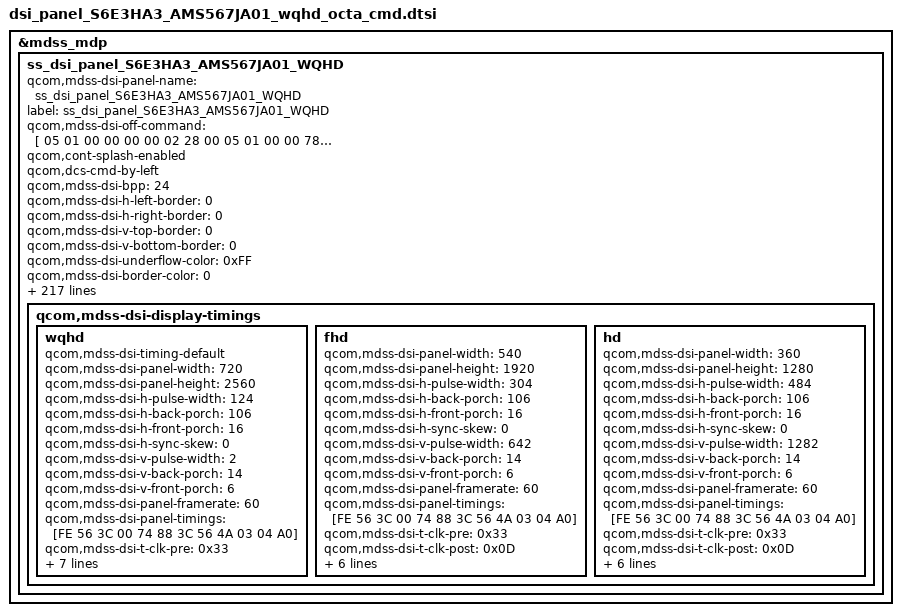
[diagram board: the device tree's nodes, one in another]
/* Copyright (c) 2012, Samsung Electronics Corporation. All rights reserved.
 *
 * This program is free software; you can redistribute it and/or modify
 * it under the terms of the GNU General Public License version 2 and
 * only version 2 as published by the Free Software Foundation.
 *
 * This program is distributed in the hope that it will be useful,
 * but WITHOUT ANY WARRANTY; without even the implied warranty of
 * MERCHANTABILITY or FITNESS FOR A PARTICULAR PURPOSE.  See the
 * GNU General Public License for more details.
 */

&mdss_mdp {
	ss_dsi_panel_S6E3HA3_AMS567JA01_WQHD: ss_dsi_panel_S6E3HA3_AMS567JA01_WQHD {
		qcom,mdss-dsi-panel-name = "ss_dsi_panel_S6E3HA3_AMS567JA01_WQHD";
		label = "ss_dsi_panel_S6E3HA3_AMS567JA01_WQHD";

		qcom,mdss-dsi-off-command=[
			05 01 00 00 00 00 02 28 00
			05 01 00 00 78 00 02 10 00	/* wait 120ms(0x78) */
		];

		qcom,cont-splash-enabled;
		qcom,dcs-cmd-by-left;
		/*qcom,cmd-sync-wait-broadcast;*/
		/*qcom,cmd-sync-wait-trigger;*/
		/*qcom,mdss-dsi-fbc-enable=*/
		/*qcom,mdss-dsi-fbc-bpp=*/
		/*qcom,mdss-dsi-fbc-packing=*/
		/*qcom,mdss-dsi-fbc-quant-error=*/
		/*qcom,mdss-dsi-fbc-bias=*/
		/*qcom,mdss-dsi-fbc-pat-mode=*/
		/*qcom,mdss-dsi-fbc-vlc-mode=*/
		/*qcom,mdss-dsi-fbc-bflc-mode=*/
		/*qcom,mdss-dsi-fbc-h-line-budget=*/
		/*qcom,mdss-dsi-fbc-budget-ctrl=*/
		/*qcom,mdss-dsi-fbc-block-budget=*/
		/*qcom,mdss-dsi-fbc-lossless-threshold=*/
		/*qcom,mdss-dsi-fbc-lossy-threshold=*/
		/*qcom,mdss-dsi-fbc-rgb-threshold=*/
		/*qcom,mdss-dsi-fbc-lossy-mode-idx=*/

		qcom,mdss-dsi-bpp = <24>;
		qcom,mdss-dsi-h-left-border = <0>;
		qcom,mdss-dsi-h-right-border = <0>;
		qcom,mdss-dsi-v-top-border = <0>;
		qcom,mdss-dsi-v-bottom-border = <0>;

		qcom,mdss-dsi-underflow-color = <0xFF>;
		qcom,mdss-dsi-border-color = <0>;

		/*qcom,mdss-dsi-pan-enable-dynamic-fps=*/
		/*qcom,mdss-dsi-pan-fps-update=*/

		qcom,mdss-dsi-bl-pmic-control-type = "bl_ctrl_dcs";
		/*qcom,mdss-dsi-bl-pmic-bank-select=*/
		/*qcom,mdss-dsi-bl-pmic-pwm-frequency=*/
		/*qcom,mdss-dsi-pwm-gpio=*/

		qcom,mdss-dsi-bl-min-level = <1>;
		qcom,mdss-dsi-bl-max-level = <365>;
		qcom,mdss-brightness-max-level = <365>;
		qcom,mdss-dsi-interleave-mode = <0>;
		qcom,mdss-dsi-panel-type = "dsi_cmd_mode";

		/*qcom,mdss-dsi-te-check-enable; */
		qcom,mdss-dsi-te-using-te-pin;
		qcom,mdss-dsi-te-pin-select = <1>;

		qcom,mdss-dsi-te-dcs-command = <1>;
		qcom,mdss-dsi-wr-mem-start = <0x2C>;
		qcom,mdss-dsi-wr-mem-continue = <0x3C>;

		/* CMD mode panel doesn't need below stuff */
		/*qcom,mdss-dsi-h-sync-pulse=*/
		/*qcom,mdss-dsi-hfp-power-mode=*/
		/*qcom,mdss-dsi-hbp-power-mode=*/
		/*qcom,mdss-dsi-hsa-power-mode=*/
		/*qcom,mdss-dsi-last-line-interleave=*/
		/*qcom,mdss-dsi-bllp-eof-power-mode=*/
		/*qcom,mdss-dsi-bllp-power-mode=*/
		/*qcom,mdss-dsi-traffic-mode=*/

		qcom,mdss-dsi-pixel-packing = "loose";

		qcom,mdss-dsi-virtual-channel-id = <0>;
		qcom,mdss-dsi-color-order = "rgb_swap_rgb";
		qcom,mdss-dsi-lane-0-state;
		qcom,mdss-dsi-lane-1-state;
		qcom,mdss-dsi-lane-2-state;
		qcom,mdss-dsi-lane-3-state;
		qcom,mdss-dsi-lane-map = "lane_map_0123";

		qcom,mdss-dsi-t-clk-pre = <0x33>;
		qcom,mdss-dsi-t-clk-post = <0x0D>;

		qcom,mdss-dsi-stream = <0>;
		qcom,mdss-dsi-mdp-trigger = "none";
		qcom,mdss-dsi-dma-trigger = "trigger_sw";
		qcom,mdss-dsi-panel-framerate = <60>;
/*		qcom,mdss-dsi-panel-clockrate = <980500000>;*/

		qcom,mdss-dsi-off-command-state = "dsi_hs_mode";

		qcom,mdss-pan-physical-width-dimension = <63>; /* 63.36*/
		qcom,mdss-pan-physical-height-dimension = <113>; /* 112.64 */

		qcom,mdss-dsi-panel-mode-gpio-state = "invalid";

		/*qcom,mdss-tear-check-disable*/
		/*qcom,mdss-tear-check-sync-cfg-height = <2576>;*/
		/*qcom,mdss-tear-check-sync-init-val=*/
		/*qcom,mdss-tear-check-sync-threshold-start=*/
		/*qcom,mdss-tear-check-sync-threshold-continue=*/
		/*qcom,mdss-tear-check-start-pos=*/
		/*qcom,mdss-tear-check-rd-ptr-trigger-intr=*/
		/*qcom,mdss-tear-check-frame-rate=*/

		qcom,mdss-dsi-reset-sequence = <1 5>, <0 5>, <1 5>;
		qcom,partial-update-enabled;
		qcom,partial-update-roi-merge;

		/*qcom,mdss-dsi-horizontal-line-idle*/

		qcom,mdss-dsi-lp11-init;
		qcom,mdss-dsi-init-delay-us = <1000>;

		qcom,mdss-dsi-rx-eot-ignore;
		qcom,mdss-dsi-tx-eot-append;

		qcom,ulps-enabled;
		/* qcom,suspend-ulps-enabled; */
		qcom,esd-check-enabled;
		qcom,mdss-dsi-panel-status-check-mode ="reg_read_irq";
		qcom,mdss-dsi-panel-status-value=<1>;
		qcom,mdss-dsi-panel-status-irq-trigger1 = "rising";
		qcom,mdss-dsi-panel-status-irq-trigger2 = "falling";

		samsung,esd_recovery_1_tx_cmds_revA = [
			07 00 00 00 00 00 01 00
			05 00 00 00 00 00 01 38
			05 00 00 00 00 00 01 2c
			29 00 00 00 00 00 03 F0 5A 5A
			29 00 00 00 00 00 05 F6 43 17 37 50
			29 01 00 00 00 00 03 F0 A5 A5
		];

		samsung,esd_recovery_2_tx_cmds_revA = [
			07 00 00 00 00 00 01 00
			05 00 00 00 00 00 01 38
			05 00 00 00 00 00 01 2c
			29 00 00 00 00 00 03 F0 5A 5A
			29 00 00 00 00 00 05 F6 43 17 37 10
			29 01 00 00 00 00 03 F0 A5 A5
		];

/*
* ************************************************************************************************************************************
*
*
*			Below  parameters are samsung dependent thigs
*
*
* ************************************************************************************************************************************
*/
		samsung,support_panel_max = <1>;
		samsung,hw-config = "split_dsi";
		samsung,panel-lpm-enable;
		samsung,support_irc;
		samsung,elvss_interpolation_temperature = <(-15)>;
		samsung,support_factory_panel_swap;
		samsung,support_multires;

		/*
		* ************************************************************************************************************************
		*  Tx
		* ************************************************************************************************************************
		*/

		samsung,level1_key_enable_tx_cmds_revA = [
			29 01 00 00 00 00 03 F0 5A 5A
		];
		samsung,level1_key_disable_tx_cmds_revA = [
			29 01 00 00 00 00 03 F0 A5 A5
		];
		samsung,level2_key_enable_tx_cmds_revA = [
			29 01 00 00 00 00 03 F2 5A 5A
		];
		samsung,level2_key_disable_tx_cmds_revA = [
			29 01 00 00 00 00 03 F2 A5 A5
		];

		samsung,packet_size_tx_cmds_revA = [
			37 01 00 00 00 00 02 07 00
		];

		samsung,reg_read_pos_tx_cmds_revA = [
			15 01 00 00 00 00 02 B0 00
		];

		samsung,manufacture_read_pre_tx_cmds_revA = [
			05 01 00 00 05 00 01 11
			29 01 00 00 00 00 03 F0 5A 5A
		];

		samsung,display_on_tx_cmds_revA = [
			29 00 00 00 00 00 03 F0 5A 5A 		/* TEST KEY1 Enable */
			29 00 00 00 00 00 02 C4 03			/* Dual DSI */
			29 00 00 00 00 00 02 F9 03			/* MIC disable */
			29 00 00 00 00 00 03 F0 A5 A5		/* TEST KEY key Disable  */
			05 01 00 00 00 00 02 29 00
		];
		samsung,display_off_tx_cmds_revA = [05 01 00 00 00 00 02 28 00];

		/*
		* ************************************************************************************************************************
		*  Rx
		* ************************************************************************************************************************
		*/

		/*
			the last byte in read commands	represent READ LENGH, like below  READ LENGH = 0x21
		*/

		samsung,manufacture_id0_rx_cmds_revA = [ 06 01 00 00 00 00 01 da 01 00];
		samsung,manufacture_id1_rx_cmds_revA = [ 06 01 00 00 00 00 01 db 01 00];
		samsung,manufacture_id2_rx_cmds_revA = [ 06 01 00 00 00 00 01 dc 01 00];

		samsung,manufacture_id_rx_cmds_revA = [ 06 01 00 00 00 00 01 04 03 00];

		samsung,manufacture_date_rx_cmds_revA = [ 06 01 00 00 00 00 01 c8 04 28];	/* read C8 41~44th , 40=0x28*/

		samsung,cell_id_rx_cmds_revA = [ 06 01 00 00 00 00 01 C8 07 28]; /* read C8 41~47th */

		samsung,ddi_id_rx_cmds_revA = [ 06 01 00 00 00 00 01 D6 05 00]; /* read D6 1th~5th */

		samsung,ldi_debug0_rx_cmds_revA = [06 01 00 00 00 00 01 0A 01 00];
		samsung,ldi_debug1_rx_cmds_revA = [06 01 00 00 00 00 01 ED 01 00];
		samsung,ldi_debug2_rx_cmds_revA = [06 01 00 00 00 00 01 EE 01 00];

		samsung,mtp_read_sysfs_rx_cmds_revA = [ 06 01 00 00 00 00 01 00 00 00];

		samsung,smart_dimming_mtp_rx_cmds_revA = [ 06 01 00 00 00 00 01 c8 23 00];

		samsung,mdnie_read_rx_cmds_revA = [ 06 01 00 00 00 00 01 A1 04 00];

		/*
		* ************************************************************************************************************************
		*  FPS change
		* ************************************************************************************************************************
		*/

		samsung,ldi_fps_change_tx_cmds_revA = [
			29 00 00 00 00 00 03 F0 5A 5A
			29 00 00 00 00 00 03 FC 5A 5A
			29 00 00 00 00 00 04 F2 63 41 C5	/* C5 => hsync timing: 453*/
			29 00 00 00 00 00 03 F0 A5 A5
			29 01 00 00 00 00 03 FC A5 A5
		];

		samsung,spi_enable_tx_cmds_revA = [
			29 01 00 00 00 00 03 F0 5A 5A
			29 01 00 00 00 00 03 FC 5A 5A
			29 01 00 00 00 00 02 B0 13
			29 01 00 00 00 00 02 D8 02
			29 01 00 00 00 00 02 B0 1F
			29 01 00 00 1E 00 02 FE 06
			29 01 00 00 00 00 03 F0 A5 A5
			29 01 00 00 00 00 03 FC A5 A5
		];

		samsung,ldi_fps_rx_cmds_revA = [06 01 00 00 00 00 01 D7 01 1A]; /* read D7 27th , 27=0x1B*/

		/*
		 * ************************************************************************************************************************
		 *   APLPM
		 * ************************************************************************************************************************
		 */

		/*
		 * The command set of R53h will be replaced with
		 * lpm 2nit or 40nit tx commnad for
		 * changing brightness level
		 */
		samsung,alpm_on_tx_cmds_revA = [
			29 01 00 00 00 00 03 F0 5A 5A		/* TEST KEY Enable */

			/* mDNIe BYPASS */
			39 01 00 00 00 00 3A
				DF 00 00 00 67 a9 0c 0c 0c 0c
				00 aa ab 00 aa ab 00 aa ab 00
				aa ab ff 00 00 ff ff 00 ff 00
				ff ff ff ff 00 ff ff 00 ff 00
				ff 00 00 ff ff 00 ff 00 ff 00
				00 ff ff 00 ff 00 ff 00
			39 01 00 00 00 00 87
				DE 00 24 96 b3 01 0e 01 00 77
				03 07 40 00 08 04 04 01 80 28
				3e 7e a0 28 18 a0 07 65 06 03
				00 40 00 00 10 00 00 30 00 00
				00 30 00 00 30 00 00 00 ff 01
				00 00 07 ff 07 ff 14 00 0a 00
				32 01 f4 0b 8a 6e 99 1b 17 1e
				1b 02 5f 03 33 02 c8 02 22 10
				10 07 07 20 2d 01 00 00 20 00
				20 00 20 00 20 00 20 00 20 00
				20 00 20 00 20 00 20 00 20 00
				20 00 20 00 20 00 20 00 20 00
				20 00 20 00 20 00 20 00 20 00
				20 00 20 00 ff
			39 01 00 00 00 00 10
				DD 01 00 00 00 00 00 00 00 00
				00 00 00 00 00 00

			29 01 00 00 00 00 02 BB C4			/* HLPM(0x54)/ALPM(0xC4) Mode On */
			29 01 00 00 00 00 02 53 03			/* ALPM/HLPM 2nit On */
			29 01 00 00 01 00 02 F7 03			/* Gamma, LTPS(AID) update */
			29 01 00 00 00 00 02 F7 00
			29 01 00 00 00 00 03 F0 A5 A5
		];

		samsung,alpm_on_tx_cmds_revD = [
			29 01 00 00 00 00 03 F0 5A 5A		/* TEST KEY Enable */

			/* mDNIe BYPASS */
			39 01 00 00 00 00 3A
				DF 00 00 00 67 a9 0c 0c 0c 0c
				00 aa ab 00 aa ab 00 aa ab 00
				aa ab ff 00 00 ff ff 00 ff 00
				ff ff ff ff 00 ff ff 00 ff 00
				ff 00 00 ff ff 00 ff 00 ff 00
				00 ff ff 00 ff 00 ff 00
			39 01 00 00 00 00 87
				DE 00 24 96 b3 01 0e 01 00 77
				03 07 40 00 08 04 04 01 80 28
				3e 7e a0 28 18 a0 07 65 06 03
				00 40 00 00 10 00 00 30 00 00
				00 30 00 00 30 00 00 00 ff 01
				00 00 07 ff 07 ff 14 00 0a 00
				32 01 f4 0b 8a 6e 99 1b 17 1e
				1b 02 5f 03 33 02 c8 02 22 10
				10 07 07 20 2d 01 00 00 20 00
				20 00 20 00 20 00 20 00 20 00
				20 00 20 00 20 00 20 00 20 00
				20 00 20 00 20 00 20 00 20 00
				20 00 20 00 20 00 20 00 20 00
				20 00 20 00 ff
			39 01 00 00 00 00 10
				DD 01 00 00 00 00 00 00 00 00
				00 00 00 00 00 00

			29 01 00 00 00 00 02 BB C4			/* HLPM(0x54)/ALPM(0xC4) Mode On */
			29 01 00 00 00 00 02 53 03			/* ALPM/HLPM 2nit On */
			29 01 00 00 00 00 02 B8 00			/* IRC Setting(IRC OFF) */
			29 01 00 00 01 00 02 F7 03			/* Gamma, LTPS(AID) update */
			29 01 00 00 00 00 02 F7 00
			29 01 00 00 00 00 03 F0 A5 A5
		];

		samsung,alpm_off_tx_cmds_revA = [
			29 01 00 00 00 00 03 F0 5A 5A	/* TEST KEY Enable */
			05 01 00 00 00 00 02 28 00		/* display off wait 20ms */

			/* image write for normal mode */

			29 01 00 00 00 00 02 53 00		/* alpm off */
			29 01 00 00 00 00 02 F7 03		/* Gamma, LTPS(AID) update */
			29 01 00 00 00 00 03 F0 A5 A5	/* TEST KEY Disable */
		];

		samsung,lpm_2nit_tx_cmds_revA = [29 01 00 00 14 00 02 53 03];
		samsung,lpm_40nit_tx_cmds_revA = [29 01 00 00 14 00 02 53 02];

		samsung,lpm_hz_none_tx_cmds_revA = [29 01 00 00 00 00 02 00 00];

		/* HLPM added on REV A or later version */
		samsung,lpm_ctrl_alpm_tx_cmds_revA = [29 01 00 00 00 00 02 BB C4];
		samsung,lpm_ctrl_hlpm_tx_cmds_revA = [29 01 00 00 00 00 02 BB 54];

		/*
		* ************************************************************************************************************************
		*  VINT
		* ************************************************************************************************************************
		*/

		samsung,vint_tx_cmds_revA = [
			29 01 00 00 00 00 03 F4 AB 1E /* 420 ~ 21cd 0 */
			29 01 00 00 00 00 03 F4 AB 1D /* 20cd 1 */
			29 01 00 00 00 00 03 F4 AB 1C /* 19cd 2 */
			29 01 00 00 00 00 03 F4 AB 1B /* 17cd 3 */
			29 01 00 00 00 00 03 F4 AB 1A /* 16cd 4 */
			29 01 00 00 00 00 03 F4 AB 19 /* 15cd 5 */
			29 01 00 00 00 00 03 F4 AB 18 /* 14cd 6 */
			29 01 00 00 00 00 03 F4 AB 17 /* 13cd 7 */
			29 01 00 00 00 00 03 F4 AB 16 /* 12cd 8 */
			29 01 00 00 00 00 03 F4 AB 15 /* 11cd 9 */
			29 01 00 00 00 00 03 F4 AB 14 /* 10cd 10 */
			29 01 00 00 00 00 03 F4 AB 13 /* 9cd 11 */
			29 01 00 00 00 00 03 F4 AB 12 /* 8cd 12 */
			29 01 00 00 00 00 03 F4 AB 11 /* 7cd 13 */
			29 01 00 00 00 00 03 F4 AB 10 /* 6 ~ 2cd 14 */
		];

		samsung,vint_tx_cmds_revC = [
			29 01 00 00 00 00 03 F4 BB 1E /* 420 ~ 21cd 0 */
			29 01 00 00 00 00 03 F4 BB 1D /* 20cd 1 */
			29 01 00 00 00 00 03 F4 BB 1C /* 19cd 2 */
			29 01 00 00 00 00 03 F4 BB 1B /* 17cd 3 */
			29 01 00 00 00 00 03 F4 BB 1A /* 16cd 4 */
			29 01 00 00 00 00 03 F4 BB 19 /* 15cd 5 */
			29 01 00 00 00 00 03 F4 BB 18 /* 14cd 6 */
			29 01 00 00 00 00 03 F4 BB 17 /* 13cd 7 */
			29 01 00 00 00 00 03 F4 BB 16 /* 12cd 8 */
			29 01 00 00 00 00 03 F4 BB 15 /* 11cd 9 */
			29 01 00 00 00 00 03 F4 BB 14 /* 10cd 10 */
			29 01 00 00 00 00 03 F4 BB 13 /* 9cd 11 */
			29 01 00 00 00 00 03 F4 BB 12 /* 8cd 12 */
			29 01 00 00 00 00 03 F4 BB 11 /* 7cd 13 */
			29 01 00 00 00 00 03 F4 BB 10 /* 6 ~ 2cd 14 */
		];

		samsung,vint_map_table_revA = <
			2	14		3	14		4	14		5	14		6	14
			7	13		8	12		9	11		10	10		11	9
			12	8		13	7		14	6		15	5		16	4
			17	3		19	2		20	1		21	0		22	0
			24	0		25	0		27	0		29	0		30	0
			32	0		34	0		37	0		39	0		41	0
			44	0		47	0		50	0		53	0		56	0
			60	0		64	0		68	0		72	0		77	0
			82	0		87	0		93	0		98	0		105	0
			111	0		119	0		126	0		134	0		143	0
			152	0		162	0		172	0		183	0		195	0
			207	0		220	0		234	0		249	0		265	0
			282	0		300	0		316	0		333	0		350	0
			357	0		365	0		372	0		380	0		387	0
			395	0		403	0		412	0		420	0
		>;

		/*
		* ************************************************************************************************************************
		*  GAMMA
		* ************************************************************************************************************************
		*/

		samsung,gamma_tx_cmds_revA = [
			29 01 00 00 00 00 24		/* Brightness Condition Set - Gamma 2.2 Setting*/
			CA 01 00 01 00 01 00 80
			80 80 80 80 80 80 80 80
			80 80 80 80 80 80 80 80
			80 80 80 80 80 80 80 00
			00 00 00 00
			29 01 00 00 00 00 02 F7 03		/* Gamma, LTPS(AID) update */

			29 01 00 00 00 00 3C		/* dummy for single transmission more 100ns delay */
			00 00 00 00 00 00 00 00 00 00
			00 00 00 00 00 00 00 00 00 00
			00 00 00 00 00 00 00 00 00 00
			00 00 00 00 00 00 00 00 00 00
			00 00 00 00 00 00 00 00 00 00
			00 00 00 00 00 00 00 00 00 00

			29 01 00 00 00 00 02 F7 00
		];

		/*
		* ************************************************************************************************************************
		*  HBM
		* ************************************************************************************************************************
		*/

		samsung,enter_hbm_lux = <10000>;
		samsung,hbm_rx_cmds_revA = [ 06 01 00 00 00 00 01 B3 21 00];	/* read C8 51~65th , 50=0x32 */
		samsung,hbm2_rx_cmds_revA = [ 06 01 00 00 00 00 01 c8 14 44];	/* read C8 69~88th , 68=0x44 */

		samsung,hbm_gamma_tx_cmds_revA = [
			29 01 00 00 00 00 24		/* Brightness Condition Set - Gamma 2.2 Setting*/
				CA 01 00 01 00 01 00 80
				80 80 80 80 80 80 80 80
				80 80 80 80 80 80 80 80
				80 80 80 80 80 80 80 00
				00 00 00 00
		];

		samsung,hbm_etc_tx_cmds_revA = [
			29 00 00 00 00 00 0B B1 54 20 1A 33 5E 8C B3 D9 00 0A	/* AID 0% */
			29 01 00 00 00 00 03 B5 BC 00		/* ELVSS 2th elvss_offset */
			29 01 00 00 00 00 02 B0 15		/* ELVSS Setting */
			29 01 00 00 00 00 02 B5 00		/* ELVSS 22th Setting */
			29 01 00 00 00 00 05 B4 50 7F 12 0A 	 /* 1th : 0x50 32frame avg, 2th : 0x7F start point 50%, 4th: 0x0A ACL 8% */
			29 01 00 00 00 00 02 55 02		/* ACL ON */
			29 01 00 00 00 00 03 F4 AB 1E		/* VINT set*/
			29 01 00 00 00 00 02 F7 03
			29 01 00 00 00 00 02 F7 00
		];

		samsung,hbm_etc_tx_cmds_revC = [
			29 00 00 00 00 00 0B B1 54 20 1A 33 5E 8C B3 D9 00 0A	/* AID 0% */
			29 01 00 00 00 00 03 B5 BC 00		/* ELVSS 2th elvss_offset */
			29 01 00 00 00 00 02 B0 15		/* ELVSS Setting */
			29 01 00 00 00 00 02 B5 00		/* ELVSS 22th Setting */
			29 01 00 00 00 00 05 B4 50 7F 12 0A 	 /* 1th : 0x50 32frame avg, 2th : 0x7F start point 50%, 4th: 0x0A ACL 8% */
			29 01 00 00 00 00 02 55 02		/* ACL ON */
			29 01 00 00 00 00 03 F4 BB 1E		/* VINT set*/
			29 01 00 00 00 00 02 F7 03
			29 01 00 00 00 00 02 F7 00
		];

		samsung,hbm_irc_tx_cmds_revA = [
			29 00 00 00 00 00 15 B8 00 00
				00 00 00 00 00 00 00 00 00
				00 00 00 00 00 00 00 00 00
		];

		samsung,panel-hbm-off-cmds_revA = [
			15 01 00 00 00 00 02 53 00		/* HBM off*/
		];

		samsung,ccb_on_tx_cmds_revA = [
			29 01 00 00 00 00 03 B7 00 3F
		];

		samsung,ccb_off_tx_cmds_revA = [
			29 01 00 00 00 00 03 B7 00 2A
		];

		/*
		* ************************************************************************************************************************
		*  IRC
		* ************************************************************************************************************************
		*/

		samsung,irc_tx_cmds_revA = [
			29 00 00 00 00 00 15 B8 00 00
				00 00 00 00 00 00 00 00 00
				00 00 00 00 00 00 00 00 00
		];

		samsung,irc_off_tx_cmds_revA = [
			29 01 00 00 00 00 02 B8 00	 /* IRC OFF */
		];

		/*
		* ************************************************************************************************************************
		* AID command list and mappings
		* ************************************************************************************************************************
		*/
		samsung,aid_tx_cmds_revA = [
			29 01 00 00 00 00 0B B1 54 20 1A 33 5E 8C B3 D9 90 DE
			29 01 00 00 00 00 0B B1 54 20 1A 33 5E 8C B3 D9 90 C1
			29 01 00 00 00 00 0B B1 54 20 1A 33 5E 8C B3 D9 90 A4
			29 01 00 00 00 00 0B B1 54 20 1A 33 5E 8C B3 D9 90 80
			29 01 00 00 00 00 0B B1 54 20 1A 33 5E 8C B3 D9 90 64
			29 01 00 00 00 00 0B B1 54 20 1A 33 5E 8C B3 D9 90 4F
			29 01 00 00 00 00 0B B1 54 20 1A 33 5E 8C B3 D9 90 30
			29 01 00 00 00 00 0B B1 54 20 1A 33 5E 8C B3 D9 90 1A
			29 01 00 00 00 00 0B B1 54 20 1A 33 5E 8C B3 D9 90 01
			29 01 00 00 00 00 0B B1 54 20 1A 33 5E 8C B3 D9 80 EE
			29 01 00 00 00 00 0B B1 54 20 1A 33 5E 8C B3 D9 80 DB
			29 01 00 00 00 00 0B B1 54 20 1A 33 5E 8C B3 D9 80 C4
			29 01 00 00 00 00 0B B1 54 20 1A 33 5E 8C B3 D9 80 B1
			29 01 00 00 00 00 0B B1 54 20 1A 33 5E 8C B3 D9 80 9F
			29 01 00 00 00 00 0B B1 54 20 1A 33 5E 8C B3 D9 80 8D
			29 01 00 00 00 00 0B B1 54 20 1A 33 5E 8C B3 D9 80 7A
			29 01 00 00 00 00 0B B1 54 20 1A 33 5E 8C B3 D9 80 50
			29 01 00 00 00 00 0B B1 54 20 1A 33 5E 8C B3 D9 80 40
			29 01 00 00 00 00 0B B1 54 20 1A 33 5E 8C B3 D9 80 2B
			29 01 00 00 00 00 0B B1 54 20 1A 33 5E 8C B3 D9 80 14
			29 01 00 00 00 00 0B B1 54 20 1A 33 5E 8C B3 D9 70 E4
			29 01 00 00 00 00 0B B1 54 20 1A 33 5E 8C B3 D9 70 CD
			29 01 00 00 00 00 0B B1 54 20 1A 33 5E 8C B3 D9 70 A1
			29 01 00 00 00 00 0B B1 54 20 1A 33 5E 8C B3 D9 70 70
			29 01 00 00 00 00 0B B1 54 20 1A 33 5E 8C B3 D9 70 56
			29 01 00 00 00 00 0B B1 54 20 1A 33 5E 8C B3 D9 70 29
			29 01 00 00 00 00 0B B1 54 20 1A 33 5E 8C B3 D9 60 F9
			29 01 00 00 00 00 0B B1 54 20 1A 33 5E 8C B3 D9 60 BF
			29 01 00 00 00 00 0B B1 54 20 1A 33 5E 8C B3 D9 60 64
			29 01 00 00 00 00 0B B1 54 20 1A 33 5E 8C B3 D9 60 46
			29 01 00 00 00 00 0B B1 54 20 1A 33 5E 8C B3 D9 50 F9
			29 01 00 00 00 00 0B B1 54 20 1A 33 5E 8C B3 D9 50 AF
			29 01 00 00 00 00 0B B1 54 20 1A 33 5E 8C B3 D9 50 60
			29 01 00 00 00 00 0B B1 54 20 1A 33 5E 8C B3 D9 50 13
			29 01 00 00 00 00 0B B1 54 20 1A 33 5E 8C B3 D9 40 DF
			29 01 00 00 00 00 0B B1 54 20 1A 33 5E 8C B3 D9 40 60
			29 01 00 00 00 00 0B B1 54 20 1A 33 5E 8C B3 D9 30 F8
			29 01 00 00 00 00 0B B1 54 20 1A 33 5E 8C B3 D9 30 90
			29 01 00 00 00 00 0B B1 54 20 1A 33 5E 8C B3 D9 30 2B
			29 01 00 00 00 00 0B B1 54 20 1A 33 5E 8C B3 D9 30 2B
			29 01 00 00 00 00 0B B1 54 20 1A 33 5E 8C B3 D9 30 2B
			29 01 00 00 00 00 0B B1 54 20 1A 33 5E 8C B3 D9 30 2B
			29 01 00 00 00 00 0B B1 54 20 1A 33 5E 8C B3 D9 30 2B
			29 01 00 00 00 00 0B B1 54 20 1A 33 5E 8C B3 D9 30 2B
			29 01 00 00 00 00 0B B1 54 20 1A 33 5E 8C B3 D9 30 2B
			29 01 00 00 00 00 0B B1 54 20 1A 33 5E 8C B3 D9 30 2B
			29 01 00 00 00 00 0B B1 54 20 1A 33 5E 8C B3 D9 30 2B
			29 01 00 00 00 00 0B B1 54 20 1A 33 5E 8C B3 D9 30 2B
			29 01 00 00 00 00 0B B1 54 20 1A 33 5E 8C B3 D9 30 2B
			29 01 00 00 00 00 0B B1 54 20 1A 33 5E 8C B3 D9 30 2B
			29 01 00 00 00 00 0B B1 54 20 1A 33 5E 8C B3 D9 30 2B
			29 01 00 00 00 00 0B B1 54 20 1A 33 5E 8C B3 D9 30 2B
			29 01 00 00 00 00 0B B1 54 20 1A 33 5E 8C B3 D9 30 2B
			29 01 00 00 00 00 0B B1 54 20 1A 33 5E 8C B3 D9 30 49
			29 01 00 00 00 00 0B B1 54 20 1A 33 5E 8C B3 D9 20 A1
			29 01 00 00 00 00 0B B1 54 20 1A 33 5E 8C B3 D9 20 31
			29 01 00 00 00 00 0B B1 54 20 1A 33 5E 8C B3 D9 10 99
			29 01 00 00 00 00 0B B1 54 20 1A 33 5E 8C B3 D9 10 11
			29 01 00 00 00 00 0B B1 54 20 1A 33 5E 8C B3 D9 10 03
			29 01 00 00 00 00 0B B1 54 20 1A 33 5E 8C B3 D9 10 03
			29 01 00 00 00 00 0B B1 54 20 1A 33 5E 8C B3 D9 10 03
			29 01 00 00 00 00 0B B1 54 20 1A 33 5E 8C B3 D9 10 03
			29 01 00 00 00 00 0B B1 54 20 1A 33 5E 8C B3 D9 10 03
			29 01 00 00 00 00 0B B1 54 20 1A 33 5E 8C B3 D9 10 03
			29 01 00 00 00 00 0B B1 54 20 1A 33 5E 8C B3 D9 10 03
			29 01 00 00 00 00 0B B1 54 20 1A 33 5E 8C B3 D9 10 03
			29 01 00 00 00 00 0B B1 54 20 1A 33 5E 8C B3 D9 10 03
			29 01 00 00 00 00 0B B1 54 20 1A 33 5E 8C B3 D9 00 C2
			29 01 00 00 00 00 0B B1 54 20 1A 33 5E 8C B3 D9 00 8E
			29 01 00 00 00 00 0B B1 54 20 1A 33 5E 8C B3 D9 00 63
			29 01 00 00 00 00 0B B1 54 20 1A 33 5E 8C B3 D9 00 1C
			29 01 00 00 00 00 0B B1 54 20 1A 33 5E 8C B3 D9 00 0A
			29 01 00 00 00 00 0B B1 54 20 1A 33 5E 8C B3 D9 00 0A
			29 01 00 00 00 00 0B B1 54 20 1A 33 5E 8C B3 D9 00 0A
		];

		/* bl_level, Index in acl command list */
		samsung,aid_map_table_revA = <
			2	0		3	1		4	2		5	3		6	4
			7	5		8	6		9	7		10	8		11	9
			12	10		13	11		14	12		15	13		16	14
			17	15		19	16		20	17		21	18		22	19
			24	20		25	21		27	22		29	23		30	24
			32	25		34	26		37	27		39	28		41	29
			44	30		47	31		50	32		53	33		56	34
			60	35		64	36		68	36		72	36		77	36
			82	36		87	36		93	36		98	36		105	36
			111	36		119	36		126	36		134	36		143	36
			152	36		162	36		172	36		183	36		195	37
			207	38		220	39		234	40		249	41		265	41
			282	41		300	41		316	41		333	41		350	41
			357	41		365	41		372	42		380	43		387	44
			395	45		403	46		412	46		420	46
		>;

		samsung,aid_subdivision_tx_cmds_revA = [ /* revA,B (Salvia) */
			29 01 00 00 00 00 0B B1 54 20 1A 33 5E 8C B3 D9 90 E1 /* 0 */
			29 01 00 00 00 00 0B B1 54 20 1A 33 5E 8C B3 D9 90 DB /* 1 */
			29 01 00 00 00 00 0B B1 54 20 1A 33 5E 8C B3 D9 90 D5 /* 2 */
			29 01 00 00 00 00 0B B1 54 20 1A 33 5E 8C B3 D9 90 D1 /* 3 */
			29 01 00 00 00 00 0B B1 54 20 1A 33 5E 8C B3 D9 90 CF /* 4 */
			29 01 00 00 00 00 0B B1 54 20 1A 33 5E 8C B3 D9 90 CB /* 5 */
			29 01 00 00 00 00 0B B1 54 20 1A 33 5E 8C B3 D9 90 C4 /* 6 */
			29 01 00 00 00 00 0B B1 54 20 1A 33 5E 8C B3 D9 90 C1 /* 7 */
			29 01 00 00 00 00 0B B1 54 20 1A 33 5E 8C B3 D9 90 BF /* 8 */
			29 01 00 00 00 00 0B B1 54 20 1A 33 5E 8C B3 D9 90 BB /* 9 */
			29 01 00 00 00 00 0B B1 54 20 1A 33 5E 8C B3 D9 90 B5 /* 10 */
			29 01 00 00 00 00 0B B1 54 20 1A 33 5E 8C B3 D9 90 B1 /* 11 */
			29 01 00 00 00 00 0B B1 54 20 1A 33 5E 8C B3 D9 90 AF /* 12 */
			29 01 00 00 00 00 0B B1 54 20 1A 33 5E 8C B3 D9 90 A5 /* 13 */
			29 01 00 00 00 00 0B B1 54 20 1A 33 5E 8C B3 D9 90 A1 /* 14 */
			29 01 00 00 00 00 0B B1 54 20 1A 33 5E 8C B3 D9 90 9F /* 15 */
			29 01 00 00 00 00 0B B1 54 20 1A 33 5E 8C B3 D9 90 9B /* 16 */
			29 01 00 00 00 00 0B B1 54 20 1A 33 5E 8C B3 D9 90 95 /* 17 */
			29 01 00 00 00 00 0B B1 54 20 1A 33 5E 8C B3 D9 90 91 /* 18 */
			29 01 00 00 00 00 0B B1 54 20 1A 33 5E 8C B3 D9 90 84 /* 19 */
			29 01 00 00 00 00 0B B1 54 20 1A 33 5E 8C B3 D9 90 81 /* 20 */
			29 01 00 00 00 00 0B B1 54 20 1A 33 5E 8C B3 D9 90 7E /* 21 */
			29 01 00 00 00 00 0B B1 54 20 1A 33 5E 8C B3 D9 90 7B /* 22 */
			29 01 00 00 00 00 0B B1 54 20 1A 33 5E 8C B3 D9 90 78 /* 23 */
			29 01 00 00 00 00 0B B1 54 20 1A 33 5E 8C B3 D9 90 75 /* 24 */
			29 01 00 00 00 00 0B B1 54 20 1A 33 5E 8C B3 D9 90 6F /* 25 */
			29 01 00 00 00 00 0B B1 54 20 1A 33 5E 8C B3 D9 90 6C /* 26 */
			29 01 00 00 00 00 0B B1 54 20 1A 33 5E 8C B3 D9 90 68 /* 27 */
			29 01 00 00 00 00 0B B1 54 20 1A 33 5E 8C B3 D9 90 64 /* 28 */
			29 01 00 00 00 00 0B B1 54 20 1A 33 5E 8C B3 D9 90 60 /* 29 */
			29 01 00 00 00 00 0B B1 54 20 1A 33 5E 8C B3 D9 90 5B /* 30 */
			29 01 00 00 00 00 0B B1 54 20 1A 33 5E 8C B3 D9 90 58 /* 31 */
			29 01 00 00 00 00 0B B1 54 20 1A 33 5E 8C B3 D9 90 56 /* 32 */
			29 01 00 00 00 00 0B B1 54 20 1A 33 5E 8C B3 D9 90 53 /* 33 */
			29 01 00 00 00 00 0B B1 54 20 1A 33 5E 8C B3 D9 90 50 /* 34 */
			29 01 00 00 00 00 0B B1 54 20 1A 33 5E 8C B3 D9 90 43 /* 35 */
			29 01 00 00 00 00 0B B1 54 20 1A 33 5E 8C B3 D9 90 35 /* 36 */
			29 01 00 00 00 00 0B B1 54 20 1A 33 5E 8C B3 D9 90 2B /* 37 */
			29 01 00 00 00 00 0B B1 54 20 1A 33 5E 8C B3 D9 90 20 /* 38 */
			29 01 00 00 00 00 0B B1 54 20 1A 33 5E 8C B3 D9 90 16 /* 39 */
			29 01 00 00 00 00 0B B1 54 20 1A 33 5E 8C B3 D9 90 0B /* 40 */
			29 01 00 00 00 00 0B B1 54 20 1A 33 5E 8C B3 D9 80 FF /* 41 */
			29 01 00 00 00 00 0B B1 54 20 1A 33 5E 8C B3 D9 80 F4 /* 42 */
			29 01 00 00 00 00 0B B1 54 20 1A 33 5E 8C B3 D9 80 EA /* 43 */
			29 01 00 00 00 00 0B B1 54 20 1A 33 5E 8C B3 D9 80 E0 /* 44 */
			29 01 00 00 00 00 0B B1 54 20 1A 33 5E 8C B3 D9 80 D7 /* 45 */
			29 01 00 00 00 00 0B B1 54 20 1A 33 5E 8C B3 D9 80 CF /* 46 */
			29 01 00 00 00 00 0B B1 54 20 1A 33 5E 8C B3 D9 80 C5 /* 47 */
			29 01 00 00 00 00 0B B1 54 20 1A 33 5E 8C B3 D9 80 BB /* 48 */
			29 01 00 00 00 00 0B B1 54 20 1A 33 5E 8C B3 D9 80 B3 /* 49 */
			29 01 00 00 00 00 0B B1 54 20 1A 33 5E 8C B3 D9 80 AA /* 50 */
			29 01 00 00 00 00 0B B1 54 20 1A 33 5E 8C B3 D9 80 9F /* 51 */
			29 01 00 00 00 00 0B B1 54 20 1A 33 5E 8C B3 D9 80 94 /* 52 */
			29 01 00 00 00 00 0B B1 54 20 1A 33 5E 8C B3 D9 80 8D /* 53 */
			29 01 00 00 00 00 0B B1 54 20 1A 33 5E 8C B3 D9 80 85 /* 54 */
			29 01 00 00 00 00 0B B1 54 20 1A 33 5E 8C B3 D9 80 72 /* 55 */
			29 01 00 00 00 00 0B B1 54 20 1A 33 5E 8C B3 D9 80 5F /* 56 */
			29 01 00 00 00 00 0B B1 54 20 1A 33 5E 8C B3 D9 80 4E /* 57 */
			29 01 00 00 00 00 0B B1 54 20 1A 33 5E 8C B3 D9 80 44 /* 58 */
			29 01 00 00 00 00 0B B1 54 20 1A 33 5E 8C B3 D9 80 3B /* 59 */
			29 01 00 00 00 00 0B B1 54 20 1A 33 5E 8C B3 D9 80 2F /* 60 */
			29 01 00 00 00 00 0B B1 54 20 1A 33 5E 8C B3 D9 80 23 /* 61 */
			29 01 00 00 00 00 0B B1 54 20 1A 33 5E 8C B3 D9 80 0B /* 62 */
			29 01 00 00 00 00 0B B1 54 20 1A 33 5E 8C B3 D9 70 F2 /* 63 */
			29 01 00 00 00 00 0B B1 54 20 1A 33 5E 8C B3 D9 70 EA /* 64 */
			29 01 00 00 00 00 0B B1 54 20 1A 33 5E 8C B3 D9 70 E1 /* 65 */
			29 01 00 00 00 00 0B B1 54 20 1A 33 5E 8C B3 D9 70 C9 /* 66 */
			29 01 00 00 00 00 0B B1 54 20 1A 33 5E 8C B3 D9 70 B0 /* 67 */
			29 01 00 00 00 00 0B B1 54 20 1A 33 5E 8C B3 D9 70 99 /* 68 */
			29 01 00 00 00 00 0B B1 54 20 1A 33 5E 8C B3 D9 70 81 /* 69 */
			29 01 00 00 00 00 0B B1 54 20 1A 33 5E 8C B3 D9 70 69 /* 70 */
			29 01 00 00 00 00 0B B1 54 20 1A 33 5E 8C B3 D9 70 51 /* 71 */
			29 01 00 00 00 00 0B B1 54 20 1A 33 5E 8C B3 D9 70 38 /* 72 */
			29 01 00 00 00 00 0B B1 54 20 1A 33 5E 8C B3 D9 70 20 /* 73 */
			29 01 00 00 00 00 0B B1 54 20 1A 33 5E 8C B3 D9 70 07 /* 74 */
			29 01 00 00 00 00 0B B1 54 20 1A 33 5E 8C B3 D9 60 E5 /* 75 */
			29 01 00 00 00 00 0B B1 54 20 1A 33 5E 8C B3 D9 60 C3 /* 76 */
			29 01 00 00 00 00 0B B1 54 20 1A 33 5E 8C B3 D9 60 A9 /* 77 */
			29 01 00 00 00 00 0B B1 54 20 1A 33 5E 8C B3 D9 60 8F /* 78 */
			29 01 00 00 00 00 0B B1 54 20 1A 33 5E 8C B3 D9 60 78 /* 79 */
			29 01 00 00 00 00 0B B1 54 20 1A 33 5E 8C B3 D9 60 61 /* 80 */
			29 01 00 00 00 00 0B B1 54 20 1A 33 5E 8C B3 D9 60 3E /* 81 */
			29 01 00 00 00 00 0B B1 54 20 1A 33 5E 8C B3 D9 60 1A /* 82 */
			29 01 00 00 00 00 0B B1 54 20 1A 33 5E 8C B3 D9 50 F3 /* 83 */
			29 01 00 00 00 00 0B B1 54 20 1A 33 5E 8C B3 D9 50 CD /* 84 */
			29 01 00 00 00 00 0B B1 54 20 1A 33 5E 8C B3 D9 50 A8 /* 85 */
			29 01 00 00 00 00 0B B1 54 20 1A 33 5E 8C B3 D9 50 83 /* 86 */
			29 01 00 00 00 00 0B B1 54 20 1A 33 5E 8C B3 D9 50 5F /* 87 */
			29 01 00 00 00 00 0B B1 54 20 1A 33 5E 8C B3 D9 50 3A /* 88 */
			29 01 00 00 00 00 0B B1 54 20 1A 33 5E 8C B3 D9 50 21 /* 89 */
			29 01 00 00 00 00 0B B1 54 20 1A 33 5E 8C B3 D9 50 09 /* 90 */
			29 01 00 00 00 00 0B B1 54 20 1A 33 5E 8C B3 D9 40 CC /* 91 */
			29 01 00 00 00 00 0B B1 54 20 1A 33 5E 8C B3 D9 40 8F /* 92 */
			29 01 00 00 00 00 0B B1 54 20 1A 33 5E 8C B3 D9 40 57 /* 93 */
			29 01 00 00 00 00 0B B1 54 20 1A 33 5E 8C B3 D9 40 20 /* 94 */
			29 01 00 00 00 00 0B B1 54 20 1A 33 5E 8C B3 D9 30 EF /* 95 */
			29 01 00 00 00 00 0B B1 54 20 1A 33 5E 8C B3 D9 30 BF /* 96 */
			29 01 00 00 00 00 0B B1 54 20 1A 33 5E 8C B3 D9 30 90 /* 97 */
			29 01 00 00 00 00 0B B1 54 20 1A 33 5E 8C B3 D9 30 60 /* 98 */
			29 01 00 00 00 00 0B B1 54 20 1A 33 5E 8C B3 D9 30 98 /* 99 */
			29 01 00 00 00 00 0B B1 54 20 1A 33 5E 8C B3 D9 30 60 /* 100 */
			29 01 00 00 00 00 0B B1 54 20 1A 33 5E 8C B3 D9 30 94 /* 101 */
			29 01 00 00 00 00 0B B1 54 20 1A 33 5E 8C B3 D9 30 60 /* 102 */
			29 01 00 00 00 00 0B B1 54 20 1A 33 5E 8C B3 D9 30 91 /* 103 */
			29 01 00 00 00 00 0B B1 54 20 1A 33 5E 8C B3 D9 30 60 /* 104 */
			29 01 00 00 00 00 0B B1 54 20 1A 33 5E 8C B3 D9 30 97 /* 105 */
			29 01 00 00 00 00 0B B1 54 20 1A 33 5E 8C B3 D9 30 60 /* 106 */
			29 01 00 00 00 00 0B B1 54 20 1A 33 5E 8C B3 D9 30 8C /* 107 */
			29 01 00 00 00 00 0B B1 54 20 1A 33 5E 8C B3 D9 30 60 /* 108 */
			29 01 00 00 00 00 0B B1 54 20 1A 33 5E 8C B3 D9 30 99 /* 109 */
			29 01 00 00 00 00 0B B1 54 20 1A 33 5E 8C B3 D9 30 60 /* 110 */
			29 01 00 00 00 00 0B B1 54 20 1A 33 5E 8C B3 D9 30 8E /* 111 */
			29 01 00 00 00 00 0B B1 54 20 1A 33 5E 8C B3 D9 30 60 /* 112 */
			29 01 00 00 00 00 0B B1 54 20 1A 33 5E 8C B3 D9 30 9A /* 113 */
			29 01 00 00 00 00 0B B1 54 20 1A 33 5E 8C B3 D9 30 60 /* 114 */
			29 01 00 00 00 00 0B B1 54 20 1A 33 5E 8C B3 D9 30 90 /* 115 */
			29 01 00 00 00 00 0B B1 54 20 1A 33 5E 8C B3 D9 30 60 /* 116 */
			29 01 00 00 00 00 0B B1 54 20 1A 33 5E 8C B3 D9 30 93 /* 117 */
			29 01 00 00 00 00 0B B1 54 20 1A 33 5E 8C B3 D9 30 60 /* 118 */
			29 01 00 00 00 00 0B B1 54 20 1A 33 5E 8C B3 D9 30 96 /* 119 */
			29 01 00 00 00 00 0B B1 54 20 1A 33 5E 8C B3 D9 30 60 /* 120 */
			29 01 00 00 00 00 0B B1 54 20 1A 33 5E 8C B3 D9 30 93 /* 121 */
			29 01 00 00 00 00 0B B1 54 20 1A 33 5E 8C B3 D9 30 60 /* 122 */
			29 01 00 00 00 00 0B B1 54 20 1A 33 5E 8C B3 D9 30 95 /* 123 */
			29 01 00 00 00 00 0B B1 54 20 1A 33 5E 8C B3 D9 30 60 /* 124 */
			29 01 00 00 00 00 0B B1 54 20 1A 33 5E 8C B3 D9 30 92 /* 125 */
			29 01 00 00 00 00 0B B1 54 20 1A 33 5E 8C B3 D9 30 60 /* 126 */
			29 01 00 00 00 00 0B B1 54 20 1A 33 5E 8C B3 D9 30 7D /* 127 */
			29 01 00 00 00 00 0B B1 54 20 1A 33 5E 8C B3 D9 30 49 /* 128 */
			29 01 00 00 00 00 0B B1 54 20 1A 33 5E 8C B3 D9 30 30 /* 129 */
			29 01 00 00 00 00 0B B1 54 20 1A 33 5E 8C B3 D9 30 17 /* 130 */
			29 01 00 00 00 00 0B B1 54 20 1A 33 5E 8C B3 D9 20 FD /* 131 */
			29 01 00 00 00 00 0B B1 54 20 1A 33 5E 8C B3 D9 20 E4 /* 132 */
			29 01 00 00 00 00 0B B1 54 20 1A 33 5E 8C B3 D9 20 CB /* 133 */
			29 01 00 00 00 00 0B B1 54 20 1A 33 5E 8C B3 D9 20 B2 /* 134 */
			29 01 00 00 00 00 0B B1 54 20 1A 33 5E 8C B3 D9 20 99 /* 135 */
			29 01 00 00 00 00 0B B1 54 20 1A 33 5E 8C B3 D9 20 89 /* 136 */
			29 01 00 00 00 00 0B B1 54 20 1A 33 5E 8C B3 D9 20 79 /* 137 */
			29 01 00 00 00 00 0B B1 54 20 1A 33 5E 8C B3 D9 20 69 /* 138 */
			29 01 00 00 00 00 0B B1 54 20 1A 33 5E 8C B3 D9 20 59 /* 139 */
			29 01 00 00 00 00 0B B1 54 20 1A 33 5E 8C B3 D9 20 49 /* 140 */
			29 01 00 00 00 00 0B B1 54 20 1A 33 5E 8C B3 D9 20 39 /* 141 */
			29 01 00 00 00 00 0B B1 54 20 1A 33 5E 8C B3 D9 20 29 /* 142 */
			29 01 00 00 00 00 0B B1 54 20 1A 33 5E 8C B3 D9 20 13 /* 143 */
			29 01 00 00 00 00 0B B1 54 20 1A 33 5E 8C B3 D9 10 FD /* 144 */
			29 01 00 00 00 00 0B B1 54 20 1A 33 5E 8C B3 D9 10 E7 /* 145 */
			29 01 00 00 00 00 0B B1 54 20 1A 33 5E 8C B3 D9 10 D2 /* 146 */
			29 01 00 00 00 00 0B B1 54 20 1A 33 5E 8C B3 D9 10 BC /* 147 */
			29 01 00 00 00 00 0B B1 54 20 1A 33 5E 8C B3 D9 10 A6 /* 148 */
			29 01 00 00 00 00 0B B1 54 20 1A 33 5E 8C B3 D9 10 90 /* 149 */
			29 01 00 00 00 00 0B B1 54 20 1A 33 5E 8C B3 D9 10 7F /* 150 */
			29 01 00 00 00 00 0B B1 54 20 1A 33 5E 8C B3 D9 10 6F /* 151 */
			29 01 00 00 00 00 0B B1 54 20 1A 33 5E 8C B3 D9 10 5E /* 152 */
			29 01 00 00 00 00 0B B1 54 20 1A 33 5E 8C B3 D9 10 4E /* 153 */
			29 01 00 00 00 00 0B B1 54 20 1A 33 5E 8C B3 D9 10 3D /* 154 */
			29 01 00 00 00 00 0B B1 54 20 1A 33 5E 8C B3 D9 10 2C /* 155 */
			29 01 00 00 00 00 0B B1 54 20 1A 33 5E 8C B3 D9 10 1C /* 156 */
			29 01 00 00 00 00 0B B1 54 20 1A 33 5E 8C B3 D9 10 0B /* 157 */
			29 01 00 00 00 00 0B B1 54 20 1A 33 5E 8C B3 D9 10 72 /* 158 */
			29 01 00 00 00 00 0B B1 54 20 1A 33 5E 8C B3 D9 10 60 /* 159 */
			29 01 00 00 00 00 0B B1 54 20 1A 33 5E 8C B3 D9 10 4F /* 160 */
			29 01 00 00 00 00 0B B1 54 20 1A 33 5E 8C B3 D9 10 3D /* 161 */
			29 01 00 00 00 00 0B B1 54 20 1A 33 5E 8C B3 D9 10 2C /* 162 */
			29 01 00 00 00 00 0B B1 54 20 1A 33 5E 8C B3 D9 10 1A /* 163 */
			29 01 00 00 00 00 0B B1 54 20 1A 33 5E 8C B3 D9 10 09 /* 164 */
			29 01 00 00 00 00 0B B1 54 20 1A 33 5E 8C B3 D9 00 F7 /* 165 */
			29 01 00 00 00 00 0B B1 54 20 1A 33 5E 8C B3 D9 10 74 /* 166 */
			29 01 00 00 00 00 0B B1 54 20 1A 33 5E 8C B3 D9 10 65 /* 167 */
			29 01 00 00 00 00 0B B1 54 20 1A 33 5E 8C B3 D9 10 55 /* 168 */
			29 01 00 00 00 00 0B B1 54 20 1A 33 5E 8C B3 D9 10 45 /* 169 */
			29 01 00 00 00 00 0B B1 54 20 1A 33 5E 8C B3 D9 10 36 /* 170 */
			29 01 00 00 00 00 0B B1 54 20 1A 33 5E 8C B3 D9 10 26 /* 171 */
			29 01 00 00 00 00 0B B1 54 20 1A 33 5E 8C B3 D9 10 16 /* 172 */
			29 01 00 00 00 00 0B B1 54 20 1A 33 5E 8C B3 D9 10 07 /* 173 */
			29 01 00 00 00 00 0B B1 54 20 1A 33 5E 8C B3 D9 00 F7 /* 174 */
			29 01 00 00 00 00 0B B1 54 20 1A 33 5E 8C B3 D9 10 74 /* 175 */
			29 01 00 00 00 00 0B B1 54 20 1A 33 5E 8C B3 D9 10 64 /* 176 */
			29 01 00 00 00 00 0B B1 54 20 1A 33 5E 8C B3 D9 10 55 /* 177 */
			29 01 00 00 00 00 0B B1 54 20 1A 33 5E 8C B3 D9 10 45 /* 178 */
			29 01 00 00 00 00 0B B1 54 20 1A 33 5E 8C B3 D9 10 36 /* 179 */
			29 01 00 00 00 00 0B B1 54 20 1A 33 5E 8C B3 D9 10 26 /* 180 */
			29 01 00 00 00 00 0B B1 54 20 1A 33 5E 8C B3 D9 10 16 /* 181 */
			29 01 00 00 00 00 0B B1 54 20 1A 33 5E 8C B3 D9 10 07 /* 182 */
			29 01 00 00 00 00 0B B1 54 20 1A 33 5E 8C B3 D9 00 F7 /* 183 */
			29 01 00 00 00 00 0B B1 54 20 1A 33 5E 8C B3 D9 10 75 /* 184 */
			29 01 00 00 00 00 0B B1 54 20 1A 33 5E 8C B3 D9 10 67 /* 185 */
			29 01 00 00 00 00 0B B1 54 20 1A 33 5E 8C B3 D9 10 59 /* 186 */
			29 01 00 00 00 00 0B B1 54 20 1A 33 5E 8C B3 D9 10 4B /* 187 */
			29 01 00 00 00 00 0B B1 54 20 1A 33 5E 8C B3 D9 10 3D /* 188 */
			29 01 00 00 00 00 0B B1 54 20 1A 33 5E 8C B3 D9 10 2F /* 189 */
			29 01 00 00 00 00 0B B1 54 20 1A 33 5E 8C B3 D9 10 21 /* 190 */
			29 01 00 00 00 00 0B B1 54 20 1A 33 5E 8C B3 D9 10 13 /* 191 */
			29 01 00 00 00 00 0B B1 54 20 1A 33 5E 8C B3 D9 10 05 /* 192 */
			29 01 00 00 00 00 0B B1 54 20 1A 33 5E 8C B3 D9 00 F7 /* 193 */
			29 01 00 00 00 00 0B B1 54 20 1A 33 5E 8C B3 D9 10 5E /* 194 */
			29 01 00 00 00 00 0B B1 54 20 1A 33 5E 8C B3 D9 10 50 /* 195 */
			29 01 00 00 00 00 0B B1 54 20 1A 33 5E 8C B3 D9 10 41 /* 196 */
			29 01 00 00 00 00 0B B1 54 20 1A 33 5E 8C B3 D9 10 32 /* 197 */
			29 01 00 00 00 00 0B B1 54 20 1A 33 5E 8C B3 D9 10 23 /* 198 */
			29 01 00 00 00 00 0B B1 54 20 1A 33 5E 8C B3 D9 10 15 /* 199 */
			29 01 00 00 00 00 0B B1 54 20 1A 33 5E 8C B3 D9 10 06 /* 200 */
			29 01 00 00 00 00 0B B1 54 20 1A 33 5E 8C B3 D9 00 F7 /* 201 */
			29 01 00 00 00 00 0B B1 54 20 1A 33 5E 8C B3 D9 10 61 /* 202 */
			29 01 00 00 00 00 0B B1 54 20 1A 33 5E 8C B3 D9 10 54 /* 203 */
			29 01 00 00 00 00 0B B1 54 20 1A 33 5E 8C B3 D9 10 46 /* 204 */
			29 01 00 00 00 00 0B B1 54 20 1A 33 5E 8C B3 D9 10 39 /* 205 */
			29 01 00 00 00 00 0B B1 54 20 1A 33 5E 8C B3 D9 10 2C /* 206 */
			29 01 00 00 00 00 0B B1 54 20 1A 33 5E 8C B3 D9 10 1F /* 207 */
			29 01 00 00 00 00 0B B1 54 20 1A 33 5E 8C B3 D9 10 11 /* 208 */
			29 01 00 00 00 00 0B B1 54 20 1A 33 5E 8C B3 D9 10 04 /* 209 */
			29 01 00 00 00 00 0B B1 54 20 1A 33 5E 8C B3 D9 00 F7 /* 210 */
			29 01 00 00 00 00 0B B1 54 20 1A 33 5E 8C B3 D9 10 5C /* 211 */
			29 01 00 00 00 00 0B B1 54 20 1A 33 5E 8C B3 D9 10 4F /* 212 */
			29 01 00 00 00 00 0B B1 54 20 1A 33 5E 8C B3 D9 10 43 /* 213 */
			29 01 00 00 00 00 0B B1 54 20 1A 33 5E 8C B3 D9 10 36 /* 214 */
			29 01 00 00 00 00 0B B1 54 20 1A 33 5E 8C B3 D9 10 29 /* 215 */
			29 01 00 00 00 00 0B B1 54 20 1A 33 5E 8C B3 D9 10 1D /* 216 */
			29 01 00 00 00 00 0B B1 54 20 1A 33 5E 8C B3 D9 10 10 /* 217 */
			29 01 00 00 00 00 0B B1 54 20 1A 33 5E 8C B3 D9 10 04 /* 218 */
			29 01 00 00 00 00 0B B1 54 20 1A 33 5E 8C B3 D9 00 F7 /* 219 */
			29 01 00 00 00 00 0B B1 54 20 1A 33 5E 8C B3 D9 10 19 /* 220 */
			29 01 00 00 00 00 0B B1 54 20 1A 33 5E 8C B3 D9 10 0E /* 221 */
			29 01 00 00 00 00 0B B1 54 20 1A 33 5E 8C B3 D9 10 02 /* 222 */
			29 01 00 00 00 00 0B B1 54 20 1A 33 5E 8C B3 D9 00 F7 /* 223 */
			29 01 00 00 00 00 0B B1 54 20 1A 33 5E 8C B3 D9 10 1D /* 224 */
			29 01 00 00 00 00 0B B1 54 20 1A 33 5E 8C B3 D9 10 11 /* 225 */
			29 01 00 00 00 00 0B B1 54 20 1A 33 5E 8C B3 D9 10 04 /* 226 */
			29 01 00 00 00 00 0B B1 54 20 1A 33 5E 8C B3 D9 00 F7 /* 227 */
			29 01 00 00 00 00 0B B1 54 20 1A 33 5E 8C B3 D9 00 E3 /* 228 */
			29 01 00 00 00 00 0B B1 54 20 1A 33 5E 8C B3 D9 00 CF /* 229 */
			29 01 00 00 00 00 0B B1 54 20 1A 33 5E 8C B3 D9 00 BB /* 230 */
			29 01 00 00 00 00 0B B1 54 20 1A 33 5E 8C B3 D9 00 AA /* 231 */
			29 01 00 00 00 00 0B B1 54 20 1A 33 5E 8C B3 D9 00 9A /* 232 */
			29 01 00 00 00 00 0B B1 54 20 1A 33 5E 8C B3 D9 00 89 /* 233 */
			29 01 00 00 00 00 0B B1 54 20 1A 33 5E 8C B3 D9 00 78 /* 234 */
			29 01 00 00 00 00 0B B1 54 20 1A 33 5E 8C B3 D9 00 72 /* 235 */
			29 01 00 00 00 00 0B B1 54 20 1A 33 5E 8C B3 D9 00 6C /* 236 */
			29 01 00 00 00 00 0B B1 54 20 1A 33 5E 8C B3 D9 00 65 /* 237 */
			29 01 00 00 00 00 0B B1 54 20 1A 33 5E 8C B3 D9 00 5F /* 238 */
			29 01 00 00 00 00 0B B1 54 20 1A 33 5E 8C B3 D9 00 4E /* 239 */
			29 01 00 00 00 00 0B B1 54 20 1A 33 5E 8C B3 D9 00 3D /* 240 */
			29 01 00 00 00 00 0B B1 54 20 1A 33 5E 8C B3 D9 00 2D /* 241 */
			29 01 00 00 00 00 0B B1 54 20 1A 33 5E 8C B3 D9 00 1C /* 242 */
			29 01 00 00 00 00 0B B1 54 20 1A 33 5E 8C B3 D9 00 30 /* 243 */
			29 01 00 00 00 00 0B B1 54 20 1A 33 5E 8C B3 D9 00 24 /* 244 */
			29 01 00 00 00 00 0B B1 54 20 1A 33 5E 8C B3 D9 00 17 /* 245 */
			29 01 00 00 00 00 0B B1 54 20 1A 33 5E 8C B3 D9 00 0A /* 246 */
			29 01 00 00 00 00 0B B1 54 20 1A 33 5E 8C B3 D9 00 34 /* 247 */
			29 01 00 00 00 00 0B B1 54 20 1A 33 5E 8C B3 D9 00 26 /* 248 */
			29 01 00 00 00 00 0B B1 54 20 1A 33 5E 8C B3 D9 00 18 /* 249 */
			29 01 00 00 00 00 0B B1 54 20 1A 33 5E 8C B3 D9 00 0A /* 250 */
			29 01 00 00 00 00 0B B1 54 20 1A 33 5E 8C B3 D9 00 2F /* 251 */
			29 01 00 00 00 00 0B B1 54 20 1A 33 5E 8C B3 D9 00 22 /* 252 */
			29 01 00 00 00 00 0B B1 54 20 1A 33 5E 8C B3 D9 00 16 /* 253 */
			29 01 00 00 00 00 0B B1 54 20 1A 33 5E 8C B3 D9 00 0A /* 254 */
			29 01 00 00 00 00 0B B1 54 20 1A 33 5E 8C B3 D9 00 0A /* 255 */
		];

		samsung,aid_subdivision_tx_cmds_revC = [
			29 01 00 00 00 00 0B B1 54 20 1A 33 5E 8C B3 D9 90 E1 /* 0 */
			29 01 00 00 00 00 0B B1 54 20 1A 33 5E 8C B3 D9 90 DB /* 1 */
			29 01 00 00 00 00 0B B1 54 20 1A 33 5E 8C B3 D9 90 D5 /* 2 */
			29 01 00 00 00 00 0B B1 54 20 1A 33 5E 8C B3 D9 90 D1 /* 3 */
			29 01 00 00 00 00 0B B1 54 20 1A 33 5E 8C B3 D9 90 CF /* 4 */
			29 01 00 00 00 00 0B B1 54 20 1A 33 5E 8C B3 D9 90 CB /* 5 */
			29 01 00 00 00 00 0B B1 54 20 1A 33 5E 8C B3 D9 90 C5 /* 6 */
			29 01 00 00 00 00 0B B1 54 20 1A 33 5E 8C B3 D9 90 C1 /* 7 */
			29 01 00 00 00 00 0B B1 54 20 1A 33 5E 8C B3 D9 90 BF /* 8 */
			29 01 00 00 00 00 0B B1 54 20 1A 33 5E 8C B3 D9 90 BB /* 9 */
			29 01 00 00 00 00 0B B1 54 20 1A 33 5E 8C B3 D9 90 B5 /* 10 */
			29 01 00 00 00 00 0B B1 54 20 1A 33 5E 8C B3 D9 90 B1 /* 11 */
			29 01 00 00 00 00 0B B1 54 20 1A 33 5E 8C B3 D9 90 AF /* 12 */
			29 01 00 00 00 00 0B B1 54 20 1A 33 5E 8C B3 D9 90 AB /* 13 */
			29 01 00 00 00 00 0B B1 54 20 1A 33 5E 8C B3 D9 90 A1 /* 14 */
			29 01 00 00 00 00 0B B1 54 20 1A 33 5E 8C B3 D9 90 9F /* 15 */
			29 01 00 00 00 00 0B B1 54 20 1A 33 5E 8C B3 D9 90 9B /* 16 */
			29 01 00 00 00 00 0B B1 54 20 1A 33 5E 8C B3 D9 90 95 /* 17 */
			29 01 00 00 00 00 0B B1 54 20 1A 33 5E 8C B3 D9 90 91 /* 18 */
			29 01 00 00 00 00 0B B1 54 20 1A 33 5E 8C B3 D9 90 8C /* 19 */
			29 01 00 00 00 00 0B B1 54 20 1A 33 5E 8C B3 D9 90 8B /* 20 */
			29 01 00 00 00 00 0B B1 54 20 1A 33 5E 8C B3 D9 90 85 /* 21 */
			29 01 00 00 00 00 0B B1 54 20 1A 33 5E 8C B3 D9 90 81 /* 22 */
			29 01 00 00 00 00 0B B1 54 20 1A 33 5E 8C B3 D9 90 7F /* 23 */
			29 01 00 00 00 00 0B B1 54 20 1A 33 5E 8C B3 D9 90 7B /* 24 */
			29 01 00 00 00 00 0B B1 54 20 1A 33 5E 8C B3 D9 90 75 /* 25 */
			29 01 00 00 00 00 0B B1 54 20 1A 33 5E 8C B3 D9 90 71 /* 26 */
			29 01 00 00 00 00 0B B1 54 20 1A 33 5E 8C B3 D9 90 70 /* 27 */
			29 01 00 00 00 00 0B B1 54 20 1A 33 5E 8C B3 D9 90 6F /* 28 */
			29 01 00 00 00 00 0B B1 54 20 1A 33 5E 8C B3 D9 90 6B /* 29 */
			29 01 00 00 00 00 0B B1 54 20 1A 33 5E 8C B3 D9 90 65 /* 30 */
			29 01 00 00 00 00 0B B1 54 20 1A 33 5E 8C B3 D9 90 61 /* 31 */
			29 01 00 00 00 00 0B B1 54 20 1A 33 5E 8C B3 D9 90 5F /* 32 */
			29 01 00 00 00 00 0B B1 54 20 1A 33 5E 8C B3 D9 90 5B /* 33 */
			29 01 00 00 00 00 0B B1 54 20 1A 33 5E 8C B3 D9 90 56 /* 34 */
			29 01 00 00 00 00 0B B1 54 20 1A 33 5E 8C B3 D9 90 4B /* 35 */
			29 01 00 00 00 00 0B B1 54 20 1A 33 5E 8C B3 D9 90 40 /* 36 */
			29 01 00 00 00 00 0B B1 54 20 1A 33 5E 8C B3 D9 90 36 /* 37 */
			29 01 00 00 00 00 0B B1 54 20 1A 33 5E 8C B3 D9 90 2B /* 38 */
			29 01 00 00 00 00 0B B1 54 20 1A 33 5E 8C B3 D9 90 1E /* 39 */
			29 01 00 00 00 00 0B B1 54 20 1A 33 5E 8C B3 D9 90 12 /* 40 */
			29 01 00 00 00 00 0B B1 54 20 1A 33 5E 8C B3 D9 90 07 /* 41 */
			29 01 00 00 00 00 0B B1 54 20 1A 33 5E 8C B3 D9 80 FD /* 42 */
			29 01 00 00 00 00 0B B1 54 20 1A 33 5E 8C B3 D9 80 F2 /* 43 */
			29 01 00 00 00 00 0B B1 54 20 1A 33 5E 8C B3 D9 80 E7 /* 44 */
			29 01 00 00 00 00 0B B1 54 20 1A 33 5E 8C B3 D9 80 DD /* 45 */
			29 01 00 00 00 00 0B B1 54 20 1A 33 5E 8C B3 D9 80 D3 /* 46 */
			29 01 00 00 00 00 0B B1 54 20 1A 33 5E 8C B3 D9 80 CA /* 47 */
			29 01 00 00 00 00 0B B1 54 20 1A 33 5E 8C B3 D9 80 C0 /* 48 */
			29 01 00 00 00 00 0B B1 54 20 1A 33 5E 8C B3 D9 80 B6 /* 49 */
			29 01 00 00 00 00 0B B1 54 20 1A 33 5E 8C B3 D9 80 AC /* 50 */
			29 01 00 00 00 00 0B B1 54 20 1A 33 5E 8C B3 D9 80 A1 /* 51 */
			29 01 00 00 00 00 0B B1 54 20 1A 33 5E 8C B3 D9 80 96 /* 52 */
			29 01 00 00 00 00 0B B1 54 20 1A 33 5E 8C B3 D9 80 8D /* 53 */
			29 01 00 00 00 00 0B B1 54 20 1A 33 5E 8C B3 D9 80 85 /* 54 */
			29 01 00 00 00 00 0B B1 54 20 1A 33 5E 8C B3 D9 80 73 /* 55 */
			29 01 00 00 00 00 0B B1 54 20 1A 33 5E 8C B3 D9 80 60 /* 56 */
			29 01 00 00 00 00 0B B1 54 20 1A 33 5E 8C B3 D9 80 57 /* 57 */
			29 01 00 00 00 00 0B B1 54 20 1A 33 5E 8C B3 D9 80 4E /* 58 */
			29 01 00 00 00 00 0B B1 54 20 1A 33 5E 8C B3 D9 80 46 /* 59 */
			29 01 00 00 00 00 0B B1 54 20 1A 33 5E 8C B3 D9 80 3C /* 60 */
			29 01 00 00 00 00 0B B1 54 20 1A 33 5E 8C B3 D9 80 31 /* 61 */
			29 01 00 00 00 00 0B B1 54 20 1A 33 5E 8C B3 D9 80 19 /* 62 */
			29 01 00 00 00 00 0B B1 54 20 1A 33 5E 8C B3 D9 80 01 /* 63 */
			29 01 00 00 00 00 0B B1 54 20 1A 33 5E 8C B3 D9 70 F6 /* 64 */
			29 01 00 00 00 00 0B B1 54 20 1A 33 5E 8C B3 D9 70 EB /* 65 */
			29 01 00 00 00 00 0B B1 54 20 1A 33 5E 8C B3 D9 70 D4 /* 66 */
			29 01 00 00 00 00 0B B1 54 20 1A 33 5E 8C B3 D9 70 BD /* 67 */
			29 01 00 00 00 00 0B B1 54 20 1A 33 5E 8C B3 D9 70 A4 /* 68 */
			29 01 00 00 00 00 0B B1 54 20 1A 33 5E 8C B3 D9 70 8C /* 69 */
			29 01 00 00 00 00 0B B1 54 20 1A 33 5E 8C B3 D9 70 75 /* 70 */
			29 01 00 00 00 00 0B B1 54 20 1A 33 5E 8C B3 D9 70 5D /* 71 */
			29 01 00 00 00 00 0B B1 54 20 1A 33 5E 8C B3 D9 70 46 /* 72 */
			29 01 00 00 00 00 0B B1 54 20 1A 33 5E 8C B3 D9 70 2F /* 73 */
			29 01 00 00 00 00 0B B1 54 20 1A 33 5E 8C B3 D9 70 17 /* 74 */
			29 01 00 00 00 00 0B B1 54 20 1A 33 5E 8C B3 D9 60 F4 /* 75 */
			29 01 00 00 00 00 0B B1 54 20 1A 33 5E 8C B3 D9 60 D1 /* 76 */
			29 01 00 00 00 00 0B B1 54 20 1A 33 5E 8C B3 D9 60 B9 /* 77 */
			29 01 00 00 00 00 0B B1 54 20 1A 33 5E 8C B3 D9 60 A1 /* 78 */
			29 01 00 00 00 00 0B B1 54 20 1A 33 5E 8C B3 D9 60 8B /* 79 */
			29 01 00 00 00 00 0B B1 54 20 1A 33 5E 8C B3 D9 60 75 /* 80 */
			29 01 00 00 00 00 0B B1 54 20 1A 33 5E 8C B3 D9 60 53 /* 81 */
			29 01 00 00 00 00 0B B1 54 20 1A 33 5E 8C B3 D9 60 31 /* 82 */
			29 01 00 00 00 00 0B B1 54 20 1A 33 5E 8C B3 D9 60 0B /* 83 */
			29 01 00 00 00 00 0B B1 54 20 1A 33 5E 8C B3 D9 50 E6 /* 84 */
			29 01 00 00 00 00 0B B1 54 20 1A 33 5E 8C B3 D9 50 C3 /* 85 */
			29 01 00 00 00 00 0B B1 54 20 1A 33 5E 8C B3 D9 50 A0 /* 86 */
			29 01 00 00 00 00 0B B1 54 20 1A 33 5E 8C B3 D9 50 7B /* 87 */
			29 01 00 00 00 00 0B B1 54 20 1A 33 5E 8C B3 D9 50 56 /* 88 */
			29 01 00 00 00 00 0B B1 54 20 1A 33 5E 8C B3 D9 50 34 /* 89 */
			29 01 00 00 00 00 0B B1 54 20 1A 33 5E 8C B3 D9 50 11 /* 90 */
			29 01 00 00 00 00 0B B1 54 20 1A 33 5E 8C B3 D9 40 E0 /* 91 */
			29 01 00 00 00 00 0B B1 54 20 1A 33 5E 8C B3 D9 40 B0 /* 92 */
			29 01 00 00 00 00 0B B1 54 20 1A 33 5E 8C B3 D9 40 86 /* 93 */
			29 01 00 00 00 00 0B B1 54 20 1A 33 5E 8C B3 D9 40 5C /* 94 */
			29 01 00 00 00 00 0B B1 54 20 1A 33 5E 8C B3 D9 40 2A /* 95 */
			29 01 00 00 00 00 0B B1 54 20 1A 33 5E 8C B3 D9 30 F7 /* 96 */
			29 01 00 00 00 00 0B B1 54 20 1A 33 5E 8C B3 D9 30 C9 /* 97 */
			29 01 00 00 00 00 0B B1 54 20 1A 33 5E 8C B3 D9 30 9B /* 98 */
			29 01 00 00 00 00 0B B1 54 20 1A 33 5E 8C B3 D9 30 99 /* 99 */
			29 01 00 00 00 00 0B B1 54 20 1A 33 5E 8C B3 D9 30 61 /* 100 */
			29 01 00 00 00 00 0B B1 54 20 1A 33 5E 8C B3 D9 30 95 /* 101 */
			29 01 00 00 00 00 0B B1 54 20 1A 33 5E 8C B3 D9 30 61 /* 102 */
			29 01 00 00 00 00 0B B1 54 20 1A 33 5E 8C B3 D9 30 92 /* 103 */
			29 01 00 00 00 00 0B B1 54 20 1A 33 5E 8C B3 D9 30 61 /* 104 */
			29 01 00 00 00 00 0B B1 54 20 1A 33 5E 8C B3 D9 30 98 /* 105 */
			29 01 00 00 00 00 0B B1 54 20 1A 33 5E 8C B3 D9 30 61 /* 106 */
			29 01 00 00 00 00 0B B1 54 20 1A 33 5E 8C B3 D9 30 8D /* 107 */
			29 01 00 00 00 00 0B B1 54 20 1A 33 5E 8C B3 D9 30 61 /* 108 */
			29 01 00 00 00 00 0B B1 54 20 1A 33 5E 8C B3 D9 30 9A /* 109 */
			29 01 00 00 00 00 0B B1 54 20 1A 33 5E 8C B3 D9 30 61 /* 110 */
			29 01 00 00 00 00 0B B1 54 20 1A 33 5E 8C B3 D9 30 8F /* 111 */
			29 01 00 00 00 00 0B B1 54 20 1A 33 5E 8C B3 D9 30 61 /* 112 */
			29 01 00 00 00 00 0B B1 54 20 1A 33 5E 8C B3 D9 30 9B /* 113 */
			29 01 00 00 00 00 0B B1 54 20 1A 33 5E 8C B3 D9 30 61 /* 114 */
			29 01 00 00 00 00 0B B1 54 20 1A 33 5E 8C B3 D9 30 91 /* 115 */
			29 01 00 00 00 00 0B B1 54 20 1A 33 5E 8C B3 D9 30 61 /* 116 */
			29 01 00 00 00 00 0B B1 54 20 1A 33 5E 8C B3 D9 30 94 /* 117 */
			29 01 00 00 00 00 0B B1 54 20 1A 33 5E 8C B3 D9 30 61 /* 118 */
			29 01 00 00 00 00 0B B1 54 20 1A 33 5E 8C B3 D9 30 97 /* 119 */
			29 01 00 00 00 00 0B B1 54 20 1A 33 5E 8C B3 D9 30 61 /* 120 */
			29 01 00 00 00 00 0B B1 54 20 1A 33 5E 8C B3 D9 30 94 /* 121 */
			29 01 00 00 00 00 0B B1 54 20 1A 33 5E 8C B3 D9 30 61 /* 122 */
			29 01 00 00 00 00 0B B1 54 20 1A 33 5E 8C B3 D9 30 96 /* 123 */
			29 01 00 00 00 00 0B B1 54 20 1A 33 5E 8C B3 D9 30 61 /* 124 */
			29 01 00 00 00 00 0B B1 54 20 1A 33 5E 8C B3 D9 30 93 /* 125 */
			29 01 00 00 00 00 0B B1 54 20 1A 33 5E 8C B3 D9 30 61 /* 126 */
			29 01 00 00 00 00 0B B1 54 20 1A 33 5E 8C B3 D9 30 95 /* 127 */
			29 01 00 00 00 00 0B B1 54 20 1A 33 5E 8C B3 D9 30 61 /* 128 */
			29 01 00 00 00 00 0B B1 54 20 1A 33 5E 8C B3 D9 30 4E /* 129 */
			29 01 00 00 00 00 0B B1 54 20 1A 33 5E 8C B3 D9 30 3A /* 130 */
			29 01 00 00 00 00 0B B1 54 20 1A 33 5E 8C B3 D9 30 27 /* 131 */
			29 01 00 00 00 00 0B B1 54 20 1A 33 5E 8C B3 D9 30 14 /* 132 */
			29 01 00 00 00 00 0B B1 54 20 1A 33 5E 8C B3 D9 30 01 /* 133 */
			29 01 00 00 00 00 0B B1 54 20 1A 33 5E 8C B3 D9 20 ED /* 134 */
			29 01 00 00 00 00 0B B1 54 20 1A 33 5E 8C B3 D9 20 DA /* 135 */
			29 01 00 00 00 00 0B B1 54 20 1A 33 5E 8C B3 D9 20 CB /* 136 */
			29 01 00 00 00 00 0B B1 54 20 1A 33 5E 8C B3 D9 20 BC /* 137 */
			29 01 00 00 00 00 0B B1 54 20 1A 33 5E 8C B3 D9 20 AC /* 138 */
			29 01 00 00 00 00 0B B1 54 20 1A 33 5E 8C B3 D9 20 9E /* 139 */
			29 01 00 00 00 00 0B B1 54 20 1A 33 5E 8C B3 D9 20 8E /* 140 */
			29 01 00 00 00 00 0B B1 54 20 1A 33 5E 8C B3 D9 20 7F /* 141 */
			29 01 00 00 00 00 0B B1 54 20 1A 33 5E 8C B3 D9 20 70 /* 142 */
			29 01 00 00 00 00 0B B1 54 20 1A 33 5E 8C B3 D9 20 5C /* 143 */
			29 01 00 00 00 00 0B B1 54 20 1A 33 5E 8C B3 D9 20 49 /* 144 */
			29 01 00 00 00 00 0B B1 54 20 1A 33 5E 8C B3 D9 20 36 /* 145 */
			29 01 00 00 00 00 0B B1 54 20 1A 33 5E 8C B3 D9 20 22 /* 146 */
			29 01 00 00 00 00 0B B1 54 20 1A 33 5E 8C B3 D9 20 0F /* 147 */
			29 01 00 00 00 00 0B B1 54 20 1A 33 5E 8C B3 D9 10 FB /* 148 */
			29 01 00 00 00 00 0B B1 54 20 1A 33 5E 8C B3 D9 10 E8 /* 149 */
			29 01 00 00 00 00 0B B1 54 20 1A 33 5E 8C B3 D9 10 D8 /* 150 */
			29 01 00 00 00 00 0B B1 54 20 1A 33 5E 8C B3 D9 10 C8 /* 151 */
			29 01 00 00 00 00 0B B1 54 20 1A 33 5E 8C B3 D9 10 B8 /* 152 */
			29 01 00 00 00 00 0B B1 54 20 1A 33 5E 8C B3 D9 10 A8 /* 153 */
			29 01 00 00 00 00 0B B1 54 20 1A 33 5E 8C B3 D9 10 98 /* 154 */
			29 01 00 00 00 00 0B B1 54 20 1A 33 5E 8C B3 D9 10 88 /* 155 */
			29 01 00 00 00 00 0B B1 54 20 1A 33 5E 8C B3 D9 10 78 /* 156 */
			29 01 00 00 00 00 0B B1 54 20 1A 33 5E 8C B3 D9 10 68 /* 157 */
			29 01 00 00 00 00 0B B1 54 20 1A 33 5E 8C B3 D9 10 70 /* 158 */
			29 01 00 00 00 00 0B B1 54 20 1A 33 5E 8C B3 D9 10 5E /* 159 */
			29 01 00 00 00 00 0B B1 54 20 1A 33 5E 8C B3 D9 10 4D /* 160 */
			29 01 00 00 00 00 0B B1 54 20 1A 33 5E 8C B3 D9 10 3B /* 161 */
			29 01 00 00 00 00 0B B1 54 20 1A 33 5E 8C B3 D9 10 2A /* 162 */
			29 01 00 00 00 00 0B B1 54 20 1A 33 5E 8C B3 D9 10 18 /* 163 */
			29 01 00 00 00 00 0B B1 54 20 1A 33 5E 8C B3 D9 10 07 /* 164 */
			29 01 00 00 00 00 0B B1 54 20 1A 33 5E 8C B3 D9 00 F5 /* 165 */
			29 01 00 00 00 00 0B B1 54 20 1A 33 5E 8C B3 D9 10 72 /* 166 */
			29 01 00 00 00 00 0B B1 54 20 1A 33 5E 8C B3 D9 10 63 /* 167 */
			29 01 00 00 00 00 0B B1 54 20 1A 33 5E 8C B3 D9 10 53 /* 168 */
			29 01 00 00 00 00 0B B1 54 20 1A 33 5E 8C B3 D9 10 43 /* 169 */
			29 01 00 00 00 00 0B B1 54 20 1A 33 5E 8C B3 D9 10 34 /* 170 */
			29 01 00 00 00 00 0B B1 54 20 1A 33 5E 8C B3 D9 10 24 /* 171 */
			29 01 00 00 00 00 0B B1 54 20 1A 33 5E 8C B3 D9 10 14 /* 172 */
			29 01 00 00 00 00 0B B1 54 20 1A 33 5E 8C B3 D9 10 05 /* 173 */
			29 01 00 00 00 00 0B B1 54 20 1A 33 5E 8C B3 D9 00 F5 /* 174 */
			29 01 00 00 00 00 0B B1 54 20 1A 33 5E 8C B3 D9 10 72 /* 175 */
			29 01 00 00 00 00 0B B1 54 20 1A 33 5E 8C B3 D9 10 62 /* 176 */
			29 01 00 00 00 00 0B B1 54 20 1A 33 5E 8C B3 D9 10 53 /* 177 */
			29 01 00 00 00 00 0B B1 54 20 1A 33 5E 8C B3 D9 10 43 /* 178 */
			29 01 00 00 00 00 0B B1 54 20 1A 33 5E 8C B3 D9 10 34 /* 179 */
			29 01 00 00 00 00 0B B1 54 20 1A 33 5E 8C B3 D9 10 24 /* 180 */
			29 01 00 00 00 00 0B B1 54 20 1A 33 5E 8C B3 D9 10 14 /* 181 */
			29 01 00 00 00 00 0B B1 54 20 1A 33 5E 8C B3 D9 10 05 /* 182 */
			29 01 00 00 00 00 0B B1 54 20 1A 33 5E 8C B3 D9 00 F5 /* 183 */
			29 01 00 00 00 00 0B B1 54 20 1A 33 5E 8C B3 D9 10 73 /* 184 */
			29 01 00 00 00 00 0B B1 54 20 1A 33 5E 8C B3 D9 10 65 /* 185 */
			29 01 00 00 00 00 0B B1 54 20 1A 33 5E 8C B3 D9 10 57 /* 186 */
			29 01 00 00 00 00 0B B1 54 20 1A 33 5E 8C B3 D9 10 49 /* 187 */
			29 01 00 00 00 00 0B B1 54 20 1A 33 5E 8C B3 D9 10 3B /* 188 */
			29 01 00 00 00 00 0B B1 54 20 1A 33 5E 8C B3 D9 10 2D /* 189 */
			29 01 00 00 00 00 0B B1 54 20 1A 33 5E 8C B3 D9 10 1F /* 190 */
			29 01 00 00 00 00 0B B1 54 20 1A 33 5E 8C B3 D9 10 11 /* 191 */
			29 01 00 00 00 00 0B B1 54 20 1A 33 5E 8C B3 D9 10 03 /* 192 */
			29 01 00 00 00 00 0B B1 54 20 1A 33 5E 8C B3 D9 00 F5 /* 193 */
			29 01 00 00 00 00 0B B1 54 20 1A 33 5E 8C B3 D9 10 5C /* 194 */
			29 01 00 00 00 00 0B B1 54 20 1A 33 5E 8C B3 D9 10 4E /* 195 */
			29 01 00 00 00 00 0B B1 54 20 1A 33 5E 8C B3 D9 10 3F /* 196 */
			29 01 00 00 00 00 0B B1 54 20 1A 33 5E 8C B3 D9 10 30 /* 197 */
			29 01 00 00 00 00 0B B1 54 20 1A 33 5E 8C B3 D9 10 21 /* 198 */
			29 01 00 00 00 00 0B B1 54 20 1A 33 5E 8C B3 D9 10 13 /* 199 */
			29 01 00 00 00 00 0B B1 54 20 1A 33 5E 8C B3 D9 10 04 /* 200 */
			29 01 00 00 00 00 0B B1 54 20 1A 33 5E 8C B3 D9 00 F5 /* 201 */
			29 01 00 00 00 00 0B B1 54 20 1A 33 5E 8C B3 D9 10 5F /* 202 */
			29 01 00 00 00 00 0B B1 54 20 1A 33 5E 8C B3 D9 10 52 /* 203 */
			29 01 00 00 00 00 0B B1 54 20 1A 33 5E 8C B3 D9 10 44 /* 204 */
			29 01 00 00 00 00 0B B1 54 20 1A 33 5E 8C B3 D9 10 37 /* 205 */
			29 01 00 00 00 00 0B B1 54 20 1A 33 5E 8C B3 D9 10 2A /* 206 */
			29 01 00 00 00 00 0B B1 54 20 1A 33 5E 8C B3 D9 10 1D /* 207 */
			29 01 00 00 00 00 0B B1 54 20 1A 33 5E 8C B3 D9 10 0F /* 208 */
			29 01 00 00 00 00 0B B1 54 20 1A 33 5E 8C B3 D9 10 02 /* 209 */
			29 01 00 00 00 00 0B B1 54 20 1A 33 5E 8C B3 D9 00 F5 /* 210 */
			29 01 00 00 00 00 0B B1 54 20 1A 33 5E 8C B3 D9 10 5A /* 211 */
			29 01 00 00 00 00 0B B1 54 20 1A 33 5E 8C B3 D9 10 4D /* 212 */
			29 01 00 00 00 00 0B B1 54 20 1A 33 5E 8C B3 D9 10 41 /* 213 */
			29 01 00 00 00 00 0B B1 54 20 1A 33 5E 8C B3 D9 10 34 /* 214 */
			29 01 00 00 00 00 0B B1 54 20 1A 33 5E 8C B3 D9 10 27 /* 215 */
			29 01 00 00 00 00 0B B1 54 20 1A 33 5E 8C B3 D9 10 1B /* 216 */
			29 01 00 00 00 00 0B B1 54 20 1A 33 5E 8C B3 D9 10 0E /* 217 */
			29 01 00 00 00 00 0B B1 54 20 1A 33 5E 8C B3 D9 10 02 /* 218 */
			29 01 00 00 00 00 0B B1 54 20 1A 33 5E 8C B3 D9 00 F5 /* 219 */
			29 01 00 00 00 00 0B B1 54 20 1A 33 5E 8C B3 D9 10 17 /* 220 */
			29 01 00 00 00 00 0B B1 54 20 1A 33 5E 8C B3 D9 10 0C /* 221 */
			29 01 00 00 00 00 0B B1 54 20 1A 33 5E 8C B3 D9 10 00 /* 222 */
			29 01 00 00 00 00 0B B1 54 20 1A 33 5E 8C B3 D9 00 F5 /* 223 */
			29 01 00 00 00 00 0B B1 54 20 1A 33 5E 8C B3 D9 10 1B /* 224 */
			29 01 00 00 00 00 0B B1 54 20 1A 33 5E 8C B3 D9 10 0F /* 225 */
			29 01 00 00 00 00 0B B1 54 20 1A 33 5E 8C B3 D9 10 02 /* 226 */
			29 01 00 00 00 00 0B B1 54 20 1A 33 5E 8C B3 D9 00 F5 /* 227 */
			29 01 00 00 00 00 0B B1 54 20 1A 33 5E 8C B3 D9 00 E3 /* 228 */
			29 01 00 00 00 00 0B B1 54 20 1A 33 5E 8C B3 D9 00 D2 /* 229 */
			29 01 00 00 00 00 0B B1 54 20 1A 33 5E 8C B3 D9 00 C0 /* 230 */
			29 01 00 00 00 00 0B B1 54 20 1A 33 5E 8C B3 D9 00 B7 /* 231 */
			29 01 00 00 00 00 0B B1 54 20 1A 33 5E 8C B3 D9 00 AE /* 232 */
			29 01 00 00 00 00 0B B1 54 20 1A 33 5E 8C B3 D9 00 A6 /* 233 */
			29 01 00 00 00 00 0B B1 54 20 1A 33 5E 8C B3 D9 00 9D /* 234 */
			29 01 00 00 00 00 0B B1 54 20 1A 33 5E 8C B3 D9 00 91 /* 235 */
			29 01 00 00 00 00 0B B1 54 20 1A 33 5E 8C B3 D9 00 85 /* 236 */
			29 01 00 00 00 00 0B B1 54 20 1A 33 5E 8C B3 D9 00 79 /* 237 */
			29 01 00 00 00 00 0B B1 54 20 1A 33 5E 8C B3 D9 00 6D /* 238 */
			29 01 00 00 00 00 0B B1 54 20 1A 33 5E 8C B3 D9 00 5F /* 239 */
			29 01 00 00 00 00 0B B1 54 20 1A 33 5E 8C B3 D9 00 51 /* 240 */
			29 01 00 00 00 00 0B B1 54 20 1A 33 5E 8C B3 D9 00 43 /* 241 */
			29 01 00 00 00 00 0B B1 54 20 1A 33 5E 8C B3 D9 00 35 /* 242 */
			29 01 00 00 00 00 0B B1 54 20 1A 33 5E 8C B3 D9 00 30 /* 243 */
			29 01 00 00 00 00 0B B1 54 20 1A 33 5E 8C B3 D9 00 24 /* 244 */
			29 01 00 00 00 00 0B B1 54 20 1A 33 5E 8C B3 D9 00 17 /* 245 */
			29 01 00 00 00 00 0B B1 54 20 1A 33 5E 8C B3 D9 00 0A /* 246 */
			29 01 00 00 00 00 0B B1 54 20 1A 33 5E 8C B3 D9 00 34 /* 247 */
			29 01 00 00 00 00 0B B1 54 20 1A 33 5E 8C B3 D9 00 26 /* 248 */
			29 01 00 00 00 00 0B B1 54 20 1A 33 5E 8C B3 D9 00 18 /* 249 */
			29 01 00 00 00 00 0B B1 54 20 1A 33 5E 8C B3 D9 00 0A /* 250 */
			29 01 00 00 00 00 0B B1 54 20 1A 33 5E 8C B3 D9 00 2F /* 251 */
			29 01 00 00 00 00 0B B1 54 20 1A 33 5E 8C B3 D9 00 22 /* 252 */
			29 01 00 00 00 00 0B B1 54 20 1A 33 5E 8C B3 D9 00 16 /* 253 */
			29 01 00 00 00 00 0B B1 54 20 1A 33 5E 8C B3 D9 00 0A /* 254 */
			29 01 00 00 00 00 0B B1 54 20 1A 33 5E 8C B3 D9 00 0A /* 255 */
		];
		samsung,panel_multires_fhd_to_wqhd_revA = [
			29 01 00 00 20 00 03 F0 5A 5A		/* TEST KEY1 Enable */

			29 00 00 00 00 00 02 BA 01			/* scaler setup */

			29 00 00 00 00 00 05 2A 00 00 05 9F	/* CASET PASET */
			29 00 00 00 00 00 05 2B 00 00 09 FF

			29 01 00 00 00 00 03 F0 A5 A5		/* TEST KEY Disable */
		];

		samsung,panel_multires_hd_to_wqhd_revA = [
			29 01 00 00 20 00 03 F0 5A 5A		/* TEST KEY1 Enable */

			29 00 00 00 00 00 02 BA 01			/* scaler setup */

			29 00 00 00 00 00 05 2A 00 00 05 9F	/* CASET PASET */
			29 00 00 00 00 00 05 2B 00 00 09 FF

			29 01 00 00 00 00 03 F0 A5 A5		/* TEST KEY Disable */
		];

		samsung,panel_multires_fhd_revA = [
			29 01 00 00 20 00 03 F0 5A 5A		/* TEST KEY1 Enable */


			29 00 00 00 00 00 02 BA 02			/* scaler setup */

			29 00 00 00 00 00 05 2A 00 00 04 37	/* CASET PASET */
			29 00 00 00 00 00 05 2B 00 00 07 7F

			29 01 00 00 00 00 03 F0 A5 A5	/* TEST KEY Disable */
		];

		samsung,panel_multires_hd_revA = [
			29 01 00 00 20 00 03 F0 5A 5A		/* TEST KEY1 Enable */

			29 00 00 00 00 00 02 BA 00			/* scaler setup */

			29 00 00 00 00 00 05 2A 00 00 02 CF	/* CASET PASET */
			29 00 00 00 00 00 05 2B 00 00 04 FF

			29 01 00 00 00 00 03 F0 A5 A5		/* TEST KEY Disable */
		];
		/*
		* ************************************************************************************************************************
		* ACL command list and mappings
		* ************************************************************************************************************************
		*/
		samsung,acl_on_tx_cmds_revA = [
			29 01 00 00 00 00 05 B4 50 7F 12 12  /* 1th : 0x50 32frame avg, 2th : 0x7F start point 50%, 4th: 0x12 ACL 15% */
			29 01 00 00 00 00 02 55 02	/* ACL ON */
		]; /* ACL on */

		samsung,acl_percent_tx_cmds_revA = [
			29 01 00 00 00 00 05 B4 50 7F 12 0A  /* 1th : 0x50 32frame avg, 2th : 0x7F start point 50%, 4th: 0x0A ACL 8% */
			29 01 00 00 00 00 05 B4 50 7F 12 12  /* 1th : 0x50 32frame avg, 2th : 0x7F start point 50%, 4th: 0x12 ACL 15% */
		];	/* ACL 50% */

		samsung,acl_off_tx_cmds_revA = [
			29 01 00 00 00 00 05 B4 40 7F 12 00  /* 1th : 0x50 32frame avg, 2th : 0x7F start point 50%, 4th: don't care */
			29 01 00 00 00 00 02 55 00	 /* ACL OFF */
		];

		samsung,gradual_acl_tx_cmds_revA = [
			29 01 00 00 16 00 05 B4 50 7F 12 00
		];

		/* bl_level , Index in acl command list */
		samsung,acl_map_table_revA =  <
			2	1		3	1		4	1		5	1		6	1
			7	1		8	1		9	1		10	1		11	1
			12	1		13	1		14	1		15	1		16	1
			17	1		19	1		20	1		21	1		22	1
			24	1		25	1		27	1		29	1		30	1
			32	1		34	1		37	1		39	1		41	1
			44	1		47	1		50	1		53	1		56	1
			60	1		64	1		68	1		72	1		77	1
			82	1		87	1		93	1		98	1		105	1
			111	1		119	1		126	1		134	1		143	1
			152	1		162	1		172	1		183	1		195	1
			207	1		220	1		234	1		249	1		265	1
			282	1		300	1		316	1		333	1		350	1
			357	1		365	1		372	1		380	1		387	1
			395	1		403	1		412	1		420	1
		>;
		/*
		* ************************************************************************************************************************
		* ELVSS(ACL Off) command list and mappings
		* ************************************************************************************************************************
		*/

		samsung,elvss_rx_cmds_revA = [ 06 01 00 00 00 00 01 B5 02 15];	/* read B5 22,23 th , 21=0x15 */

		samsung,elvss_lowtemp_tx_cmds_revA = [
			29 01 00 00 00 00 02 B0 1C /* 0xB5 29th temperature*/
			29 01 00 00 00 00 02 B5 00
			29 01 00 00 00 00 02 B0 15 /* 0xB5 22th  elvss_offset*/
			29 01 00 00 00 00 02 B5 00
		];	/* ELVSS Temperature Command */

		samsung,elvss_tx_cmds_revA = [
			29 01 00 00 00 00 03 B5 BC 0A /* 420CD 0 */
			29 01 00 00 00 00 03 B5 BC 0A /* 412CD 1 */
			29 01 00 00 00 00 03 B5 BC 0B /* 403CD 2 */
			29 01 00 00 00 00 03 B5 BC 0B /* 395CD 3 */
			29 01 00 00 00 00 03 B5 BC 0B /* 387CD 4 */
			29 01 00 00 00 00 03 B5 BC 0C /* 380CD 5 */
			29 01 00 00 00 00 03 B5 BC 0C /* 372CD 6 */
			29 01 00 00 00 00 03 B5 BC 0C /* 365CD 7 */
			29 01 00 00 00 00 03 B5 BC 0D /* 357CD 8 */
			29 01 00 00 00 00 03 B5 BC 0D /* 350CD 9 */
			29 01 00 00 00 00 03 B5 BC 0E /* 333CD 10 */
			29 01 00 00 00 00 03 B5 BC 0F /* 316CD 11 */
			29 01 00 00 00 00 03 B5 BC 0F /* 300CD 12 */
			29 01 00 00 00 00 03 B5 BC 10 /* 282CD 13 */
			29 01 00 00 00 00 03 B5 BC 11 /* 265CD 14 */
			29 01 00 00 00 00 03 B5 BC 12 /* 249CD 15 */
			29 01 00 00 00 00 03 B5 BC 12 /* 234CD 16 */
			29 01 00 00 00 00 03 B5 BC 13 /* 220CD 17 */
			29 01 00 00 00 00 03 B5 BC 13 /* 207CD 18 */
			29 01 00 00 00 00 03 B5 BC 14 /* 195CD 19 */
			29 01 00 00 00 00 03 B5 BC 14 /* 183CD 20 */
			29 01 00 00 00 00 03 B5 BC 15 /* 172CD 21 */
			29 01 00 00 00 00 03 B5 BC 15 /* 162CD 22 */
			29 01 00 00 00 00 03 B5 BC 15 /* 152CD 23 */
			29 01 00 00 00 00 03 B5 BC 15 /* 143CD 24 */
			29 01 00 00 00 00 03 B5 BC 15 /* 134CD 25 */
			29 01 00 00 00 00 03 B5 BC 15 /* 126CD 26 */
			29 01 00 00 00 00 03 B5 BC 15 /* 119CD 27 */
			29 01 00 00 00 00 03 B5 BC 16 /* 111CD 28 */
			29 01 00 00 00 00 03 B5 BC 16 /* 105CD 29 */
			29 01 00 00 00 00 03 B5 BC 16 /*  98CD 30 */
			29 01 00 00 00 00 03 B5 BC 16 /*  93CD 31 */
			29 01 00 00 00 00 03 B5 BC 16 /*  87CD 32 */
			29 01 00 00 00 00 03 B5 BC 16 /*  82CD 33 */
			29 01 00 00 00 00 03 B5 BC 16 /*  77CD 34 */

			29 01 00 00 00 00 03 B5 BC 16 /* 41 ~ 72CD 35 */
			29 01 00 00 00 00 03 B5 AC 16 /* 6 ~ 39CD 36 */

			29 01 00 00 00 00 03 B5 AC 15 /*  5CD 37 */
			29 01 00 00 00 00 03 B5 AC 14 /*  4CD 38 */
			29 01 00 00 00 00 03 B5 AC 13 /*  3CD 39 */
			29 01 00 00 00 00 03 B5 AC 12 /*  2CD 40 */
		];

		samsung,elvss_tx_cmds_revC = [
			29 01 00 00 00 00 03 B5 BC 0A /* 420CD 0 */
			29 01 00 00 00 00 03 B5 BC 0A /* 412CD 1 */
			29 01 00 00 00 00 03 B5 BC 0B /* 403CD 2 */
			29 01 00 00 00 00 03 B5 BC 0B /* 395CD 3 */
			29 01 00 00 00 00 03 B5 BC 0B /* 387CD 4 */
			29 01 00 00 00 00 03 B5 BC 0B /* 380CD 5 */
			29 01 00 00 00 00 03 B5 BC 0C /* 372CD 6 */
			29 01 00 00 00 00 03 B5 BC 0C /* 365CD 7 */
			29 01 00 00 00 00 03 B5 BC 0D /* 357CD 8 */
			29 01 00 00 00 00 03 B5 BC 0D /* 350CD 9 */
			29 01 00 00 00 00 03 B5 BC 0E /* 333CD 10 */
			29 01 00 00 00 00 03 B5 BC 0F /* 316CD 11 */
			29 01 00 00 00 00 03 B5 BC 0F /* 300CD 12 */
			29 01 00 00 00 00 03 B5 BC 10 /* 282CD 13 */
			29 01 00 00 00 00 03 B5 BC 11 /* 265CD 14 */
			29 01 00 00 00 00 03 B5 BC 12 /* 249CD 15 */
			29 01 00 00 00 00 03 B5 BC 12 /* 234CD 16 */
			29 01 00 00 00 00 03 B5 BC 13 /* 220CD 17 */
			29 01 00 00 00 00 03 B5 BC 13 /* 207CD 18 */
			29 01 00 00 00 00 03 B5 BC 14 /* 195CD 19 */
			29 01 00 00 00 00 03 B5 BC 14 /* 183CD 20 */
			29 01 00 00 00 00 03 B5 BC 15 /* 172CD 21 */
			29 01 00 00 00 00 03 B5 BC 15 /* 162CD 22 */
			29 01 00 00 00 00 03 B5 BC 15 /* 152CD 23 */
			29 01 00 00 00 00 03 B5 BC 16 /* 143CD 24 */
			29 01 00 00 00 00 03 B5 BC 16 /* 134CD 25 */
			29 01 00 00 00 00 03 B5 BC 17 /* 126CD 26 */
			29 01 00 00 00 00 03 B5 BC 17 /* 119CD 27 */
			29 01 00 00 00 00 03 B5 BC 18 /* 111CD 28 */
			29 01 00 00 00 00 03 B5 BC 18 /* 105CD 29 */
			29 01 00 00 00 00 03 B5 BC 19 /*  98CD 30 */
			29 01 00 00 00 00 03 B5 BC 19 /*  93CD 31 */
			29 01 00 00 00 00 03 B5 BC 19 /*  87CD 32 */
			29 01 00 00 00 00 03 B5 BC 1A /*  82CD 33 */
			29 01 00 00 00 00 03 B5 BC 1A /*  77CD 34 */

			29 01 00 00 00 00 03 B5 BC 1A /* 41 ~ 72CD 35 */
			29 01 00 00 00 00 03 B5 AC 1A /* 6 ~ 39CD 36 */

			29 01 00 00 00 00 03 B5 AC 19 /*  5CD 37 */
			29 01 00 00 00 00 03 B5 AC 18 /*  4CD 38 */
			29 01 00 00 00 00 03 B5 AC 17 /*  3CD 39 */
			29 01 00 00 00 00 03 B5 AC 16 /*  2CD 40 */
		];

		/* bl_level, Index in elvss command list */
		samsung,smart_acl_elvss_map_table_revA = <
			2	40		3	39		4	38		5	37		6	36
			7	36		8	36		9	36		10	36		11	36
			12	36		13	36		14	36		15	36		16	36
			17	36		19	36		20	36		21	36		22	36
			24	36		25	36		27	36		29	36		30	36
			32	36		34	36		37	36		39	36		41	35
			44	35		47	35		50	35		53	35		56	35
			60	35		64	35		68	35		72	35		77	34
			82	33		87	32		93	31		98	30		105	29
			111	28		119	27		126	26		134	25		143	24
			152	23		162	22		172	21		183	20		195	19
			207	18		220	17		234	16		249	15		265	14
			282	13		300	12		316	11		333	10		350	9
			357	8		365	7		372	6		380	5		387	4
			395	3		403	2		412	1		420	0
		>;

		/*
		* ************************************************************************************************************************
		* candela to index mappings
		* ************************************************************************************************************************
		*/
		samsung,candela_map_table_revA = <
		/*<idx>   <from>  <till> <candella> */
			0	0	0	2
			1	1	6	3
			2	7	13	4
			3	14	19	5
			4	20	27	6
			5	28	34	7
			6	35	36	8
			7	37	38	9
			8	39	40	10
			9	41	42	11
			10	43	44	12
			11	45	46	13
			12	47	48	14
			13	49	50	15
			14	51	52	16
			15	53	54	17
			16	55	56	19
			17	57	57	20
			18	58	59	21
			19	60	61	22
			20	62	63	24
			21	64	65	25
			22	66	67	27
			23	68	69	29
			24	70	70	30
			25	71	72	32
			26	73	74	34
			27	75	76	37
			28	77	78	39
			29	79	80	41
			30	81	82	44
			31	83	84	47
			32	85	86	50
			33	87	88	53
			34	89	90	56
			35	91	92	60
			36	93	94	64
			37	95	96	68
			38	97	98	72
			39	99	100	77
			40	101	102	82
			41	103	104	87
			42	105	106	93
			43	107	108	98
			44	109	110	105
			45	111	112	111
			46	113	114	119
			47	115	116	126
			48	117	118	134
			49	119	120	143
			50	121	122	152
			51	123	124	162
			52	125	126	172
			53	127	128	183
			54	129	135	195
			55	136	142	207
			56	143	149	220
			57	150	157	234
			58	158	165	249
			59	166	174	265
			60	175	183	282
			61	184	193	300
			62	194	201	316
			63	202	210	333
			64	211	219	350
			65	220	223	357
			66	224	227	365
			67	228	230	372
			68	231	234	380
			69	235	238	387
			70	239	242	395
			71	243	246	403
			72	247	250	412
			73	251	255	420
		>;

		samsung,hbm_candela_map_table_revA = <
			0	282	295	465	6
			1	296	309	488	7
			2	310	323	510	8
			3	324	336	533	9
			4	337	350	555	10
			5	351	364	578	11
			6	365	365	600	12
		>;

		/*
		* ************************************************************************************************************************
		*  HMT
		* ************************************************************************************************************************
		*/

		samsung,hmt_enabled;

		samsung,hmt_aid_tx_cmds_revA = [
			29 01 00 00 00 00 0B B1 54 20 1A 33 5E 8C B3 D9 20 03  /*10cd */
			29 01 00 00 00 00 0B B1 54 20 1A 33 5E 8C B3 D9 20 03  /*11cd */
			29 01 00 00 00 00 0B B1 54 20 1A 33 5E 8C B3 D9 20 03  /*12cd */
			29 01 00 00 00 00 0B B1 54 20 1A 33 5E 8C B3 D9 20 03  /*13cd */
			29 01 00 00 00 00 0B B1 54 20 1A 33 5E 8C B3 D9 20 03  /*14cd */
			29 01 00 00 00 00 0B B1 54 20 1A 33 5E 8C B3 D9 20 03  /*15cd */
			29 01 00 00 00 00 0B B1 54 20 1A 33 5E 8C B3 D9 20 03  /*16cd */
			29 01 00 00 00 00 0B B1 54 20 1A 33 5E 8C B3 D9 20 03  /*17cd */
			29 01 00 00 00 00 0B B1 54 20 1A 33 5E 8C B3 D9 20 03  /*19cd */
			29 01 00 00 00 00 0B B1 54 20 1A 33 5E 8C B3 D9 20 03  /*20cd */
			29 01 00 00 00 00 0B B1 54 20 1A 33 5E 8C B3 D9 20 03  /*21cd */
			29 01 00 00 00 00 0B B1 54 20 1A 33 5E 8C B3 D9 20 03  /*22cd */
			29 01 00 00 00 00 0B B1 54 20 1A 33 5E 8C B3 D9 20 03  /*23cd */
			29 01 00 00 00 00 0B B1 54 20 1A 33 5E 8C B3 D9 20 03  /*25cd */
			29 01 00 00 00 00 0B B1 54 20 1A 33 5E 8C B3 D9 20 03  /*27cd */
			29 01 00 00 00 00 0B B1 54 20 1A 33 5E 8C B3 D9 20 03  /*29cd */
			29 01 00 00 00 00 0B B1 54 20 1A 33 5E 8C B3 D9 20 03  /*31cd */
			29 01 00 00 00 00 0B B1 54 20 1A 33 5E 8C B3 D9 20 03  /*33cd */
			29 01 00 00 00 00 0B B1 54 20 1A 33 5E 8C B3 D9 20 03  /*35cd */
			29 01 00 00 00 00 0B B1 54 20 1A 33 5E 8C B3 D9 20 03  /*37cd */
			29 01 00 00 00 00 0B B1 54 20 1A 33 5E 8C B3 D9 20 03  /*39cd */
			29 01 00 00 00 00 0B B1 54 20 1A 33 5E 8C B3 D9 20 03  /*41cd */
			29 01 00 00 00 00 0B B1 54 20 1A 33 5E 8C B3 D9 20 03  /*44cd */
			29 01 00 00 00 00 0B B1 54 20 1A 33 5E 8C B3 D9 20 03  /*47cd */
			29 01 00 00 00 00 0B B1 54 20 1A 33 5E 8C B3 D9 20 03  /*50cd */
			29 01 00 00 00 00 0B B1 54 20 1A 33 5E 8C B3 D9 20 03  /*53cd */
			29 01 00 00 00 00 0B B1 54 20 1A 33 5E 8C B3 D9 20 03  /*56cd */
			29 01 00 00 00 00 0B B1 54 20 1A 33 5E 8C B3 D9 20 03  /*60cd */
			29 01 00 00 00 00 0B B1 54 20 1A 33 5E 8C B3 D9 20 03  /*64cd */
			29 01 00 00 00 00 0B B1 54 20 1A 33 5E 8C B3 D9 20 03  /*68cd */
			29 01 00 00 00 00 0B B1 54 20 1A 33 5E 8C B3 D9 20 03  /*72cd */
			29 01 00 00 00 00 0B B1 54 20 1A 33 5E 8C B3 D9 30 05  /*77cd */
			29 01 00 00 00 00 0B B1 54 20 1A 33 5E 8C B3 D9 30 05  /*82cd */
			29 01 00 00 00 00 0B B1 54 20 1A 33 5E 8C B3 D9 30 05  /*87cd */
			29 01 00 00 00 00 0B B1 54 20 1A 33 5E 8C B3 D9 30 05  /*93cd */
			29 01 00 00 00 00 0B B1 54 20 1A 33 5E 8C B3 D9 30 05  /*99cd */
			29 01 00 00 00 00 0B B1 54 20 1A 33 5E 8C B3 D9 30 05  /*105cd */
		];

		/* bl_level, Index in acl command list */
		samsung,hmt_reverse_aid_map_table_revA = <
			10	0
			11	1
			12	2
			13	3
			14	4
			15	5
			16	6
			17	7
			19	8
			20	9
			21	10
			22	11
			23	12
			25	13
			27	14
			29	15
			31	16
			33	17
			35	18
			37	19
			39	20
			41	21
			44	22
			47	23
			50	24
			53	25
			56	26
			60	27
			64	28
			68	29
			72	30
			77	31
			82	32
			87	33
			93	34
			99	35
			105	36
		>;

		samsung,hmt_candela_map_table_revA = <
		/*<idx>	  <from>  <till> <candella> */
			0	0	26	10
			1	27	29	11
			2	30	31	12
			3	32	33	13
			4	34	36	14
			5	37	38	15
			6	39	41	16
			7	42	46	17
			8	47	48	19
			9	49	50	20
			10	51	53	21
			11	54	55	22
			12	56	60	23
			13	61	65	25
			14	66	70	27
			15	71	75	29
			16	76	80	31
			17	81	84	33
			18	85	89	35
			19	90	94	37
			20	95	99	39
			21	100	106	41
			22	107	114	44
			23	115	121	47
			24	122	128	50
			25	129	135	53
			26	136	145	56
			27	146	155	60
			28	156	165	64
			29	166	174	68
			30	175	186	72
			31	187	199	77
			32	200	211	82
			33	212	225	87
			34	226	240	93
			35	241	254	99
			36	255	255	105
		>;

		samsung,hmt_gamma_tx_cmds_revA = [
			29 01 00 00 00 00 24
				CA 01 00 01 00 01 00 80
				80 80 80 80 80 80 80 80
				80 80 80 80 80 80 80 80
				80 80 80 80 80 80 80 00
				00 00 00 00

			29 01 00 00 00 00 05 B4 40 7F 12 12  /* 1th : 0x50 32frame avg, 2th : 0x7F start point 50%, 4th: don't care */
			29 01 00 00 00 00 02 55 00	 /* ACL OFF */

			29 01 00 00 00 00 02 B8 00	 /* IRC OFF */

			29 01 00 00 01 00 02 F7 03		/* Gamma, LTPS(AID) update */
			29 01 00 00 00 00 02 F7 00
		];

		samsung,hmt_elvss_tx_cmds_revA = [
				29 01 00 00 00 00 02 B0 01
				29 01 00 00 00 00 03 B5 00 0A
		];

		samsung,hmt_vint_tx_cmds_revA = [
				29 01 00 00 00 00 03 F4 AB 1E
		];

		samsung,hmt_vint_tx_cmds_revC = [
				29 01 00 00 00 00 03 F4 BB 1E
		];

		samsung,hmt_enable_tx_cmds_revA = [
				29 01 00 00 00 00 03 F0 5A 5A
				29 01 00 00 00 00 0F
					B1 54 20 1A 33 5E 8C B3 D9 30
					05 00 0A 00 00 						/* AID 1-Cycle */
				29 01 00 00 01 00 02 F7 03				/* Gamma, LTPS(AID) update */
				29 01 00 00 00 00 02 F7 00
				29 01 00 00 00 00 03 F0 A5 A5
			];

		samsung,hmt_disable_tx_cmds_revA = [
				29 01 00 00 00 00 03 F0 5A 5A
				29 01 00 00 00 00 0F
					B1 54 20 1A 33 5E 8C B3 D9 30
					05 00 0A 00 80 						/* AID 4-Cycle */
				29 01 00 00 01 00 02 F7 03				/* Gamma, LTPS(AID) update */
				29 01 00 00 00 00 02 F7 00
				29 01 00 00 00 00 03 F0 A5 A5
			];

		samsung,hmt_reverse_tx_cmds_revA = [
				29 01 00 00 00 00 03 F0 5A 5A
				29 01 00 00 00 00 42 CB					/* LTPS setting */
					18 01 80 00 00 80 60 00
					00 06 05 00 00 00 02 0D
					00 15 9A 00 00 00 00 14
					00 00 00 00 9D 00 00 CA
					0A 0A 03 C5 84 CA 0A 0A
					0A CA CA CF D1 CD C3 C5
					C4 0A 0A 0A 0A 0A 0A 00
					00 0E 01 AE 27 00 00 0C
					00
				29 01 00 00 01 00 02 F7 03				/* Gamma, LTPS(AID) update */
				29 01 00 00 00 00 02 F7 00
				29 01 00 00 00 00 03 F0 A5 A5
			];
		samsung,hmt_forward_tx_cmds_revA = [
				29 01 00 00 00 00 03 F0 5A 5A
				29 01 00 00 00 00 42 CB					/* LTPS setting */
					18 01 80 00 00 80 60 00
					00 06 05 00 00 00 0A 05
					00 15 9A 00 00 00 00 08
					00 00 00 00 9D 00 00 CA
					0A 0A 03 C5 84 CA 0A 0A
					0A CA CA CF D1 4D C3 C5
					C4 0A 0A 0A 0A 0A 0A 00
					00 0E 01 7B 4D 00 00 0C
					00
				29 01 00 00 01 00 02 F7 03				/* Gamma, LTPS(AID) update */
				29 01 00 00 00 00 02 F7 00
				29 01 00 00 00 00 03 F0 A5 A5
			];
		/*
		* ************************************************************************************************************************
		*  MULTI_RESOLUTION (DSC configs were moved all to below timing set)
		* ************************************************************************************************************************
		*/

		qcom,mdss-dsi-display-timings {
			wqhd {
				qcom,mdss-dsi-timing-default;
				qcom,mdss-dsi-panel-width = <720>;
				qcom,mdss-dsi-panel-height = <2560>;
				qcom,mdss-dsi-h-pulse-width = <124>;
				qcom,mdss-dsi-h-back-porch = <106>;
				qcom,mdss-dsi-h-front-porch = <16>;
				qcom,mdss-dsi-h-sync-skew = <0>;
				qcom,mdss-dsi-v-pulse-width = <2>;
				qcom,mdss-dsi-v-back-porch = <14>;
				qcom,mdss-dsi-v-front-porch = <6>;

				qcom,mdss-dsi-panel-framerate = <60>;
				qcom,mdss-dsi-panel-timings = [FE 56 3C 00 74 88 3C 56 4A 03 04 A0];
				qcom,mdss-dsi-t-clk-pre = <0x33>;
				qcom,mdss-dsi-t-clk-post = <0x0D>;
				qcom,mdss-dsi-panel-timings-phy-v2 = [
					24 1F 08 09 05 03 04 a0
					24 1F 08 09 05 03 04 a0
					24 1F 08 09 05 03 04 a0
					24 1F 08 09 05 03 04 a0
					24 1E 08 09 05 03 04 a0
				];
				qcom,mdss-dsi-on-command = [
					29 00 00 00 05 00 03 F0 5A 5A 		/* TEST KEY1 Enable */

					05 01 00 00 05 00 01 11 			/* Sleep out */

					29 00 00 00 00 00 02 C4 03			/* Dual DSI */
					29 01 00 00 00 00 02 F9 03			/* MIC disable */

					29 00 00 00 00 00 02 35 00			/* TE Vsync ON */

					29 00 00 00 00 00 02 ED 44			/* ERR_FG */

					29 00 00 00 00 00 14 C2				/* pentime control setting */
					00 00 D8 D8 00 80 2B 05
					08 0E 07 0B 05 0D 0A 15
					13 20 1E

					29 00 00 00 00 00 02 BA 01			/* scaler setup */

					29 00 00 00 00 00 05 2A 00 00 05 9F	/* CASET PASET */
					29 00 00 00 00 00 05 2B 00 00 09 FF

					29 00 00 00 00 00 24				/* Brightness condition set */
					CA
					01 00 01 00 01 00
					80 80 80
					80 80 80
					80 80 80
					80 80 80
					80 80 80
					80 80 80
					80 80 80
					80 80 80
					00 00 00
					00 00
					29 00 00 00 00 00 0B B1 54 20 1A 33 5E 8C B3 D9	00 0A	/* AID 0% */
					29 00 00 00 00 00 03 B5 BC 4A		/* ELVSS Setting:CAPS ON : acl off */
										/* defualt ELVSS is 0x0A(-4.5V),
										 * but set 0x4A(-2.9V) to avoid glitter issue (2V more diff between ELVSS and VINT)
										 */
					29 00 00 00 00 00 03 F4 AB 1E		/* VINT set */
					29 00 00 00 00 00 02 55 00			/* acl off */

					29 01 00 00 78 00 02 F7 03			/* Gamma, LTPS(AID) update wait more 100ns */
					29 00 00 00 00 00 02 F7 00

					29 01 00 00 00 00 03 F0 A5 A5		/* TEST KEY key Disable  */
				];
				qcom,mdss-dsi-on-command-state = "dsi_lp_mode";
				qcom,panel-roi-alignment=<8 1 8 1 8 1>;
			};
			fhd {
				qcom,mdss-dsi-panel-width = <540>;
				qcom,mdss-dsi-panel-height = <1920>;
				qcom,mdss-dsi-h-pulse-width = <304>;
				qcom,mdss-dsi-h-back-porch = <106>;
				qcom,mdss-dsi-h-front-porch = <16>;
				qcom,mdss-dsi-h-sync-skew = <0>;
				qcom,mdss-dsi-v-pulse-width = <642>;//+640
				qcom,mdss-dsi-v-back-porch = <14>;
				qcom,mdss-dsi-v-front-porch = <6>;

				qcom,mdss-dsi-panel-framerate = <60>;
				qcom,mdss-dsi-panel-timings = [FE 56 3C 00 74 88 3C 56 4A 03 04 A0];
				qcom,mdss-dsi-t-clk-pre = <0x33>;
				qcom,mdss-dsi-t-clk-post = <0x0D>;
				qcom,mdss-dsi-panel-timings-phy-v2 = [
					24 1F 08 09 05 03 04 a0
					24 1F 08 09 05 03 04 a0
					24 1F 08 09 05 03 04 a0
					24 1F 08 09 05 03 04 a0
					24 1E 08 09 05 03 04 a0
				];
				qcom,mdss-dsi-on-command = [
					29 00 00 00 05 00 03 F0 5A 5A 		/* TEST KEY1 Enable */

					05 01 00 00 05 00 01 11 			/* Sleep out */

					29 00 00 00 00 00 02 C4 03			/* Dual DSI */
					29 01 00 00 00 00 02 F9 03			/* MIC disable */

					29 00 00 00 00 00 02 35 00			/* TE Vsync ON */

					29 00 00 00 00 00 02 ED 44			/* ERR_FG */

					29 00 00 00 00 00 14 C2				/* pentime control setting */
					00 00 D8 D8 00 80 2B 05
					08 0E 07 0B 05 0D 0A 15
					13 20 1E

					29 00 00 00 00 00 02 BA 02			/* scaler setup */

					29 00 00 00 00 00 05 2A 00 00 04 37	/* CASET PASET */
					29 00 00 00 00 00 05 2B 00 00 07 7F

					29 00 00 00 00 00 24				/* Brightness condition set */
					CA
					01 00 01 00 01 00
					80 80 80
					80 80 80
					80 80 80
					80 80 80
					80 80 80
					80 80 80
					80 80 80
					80 80 80
					00 00 00
					00 00
					29 00 00 00 00 00 0B B1 54 20 1A 33 5E 8C B3 D9	00 0A	/* AID 0% */
					29 00 00 00 00 00 03 B5 BC 4A		/* ELVSS Setting:CAPS ON : acl off */
												/* defualt ELVSS is 0x0A(-4.5V),
												 * but set 0x4A(-2.9V) to avoid glitter issue (2V more diff between ELVSS and VINT)
												 */
					29 00 00 00 00 00 03 F4 AB 1E		/* VINT set */
					29 00 00 00 00 00 02 55 00			/* acl off */

					29 01 00 00 78 00 02 F7 03			/* Gamma, LTPS(AID) update wait more 100ns */
					29 00 00 00 00 00 02 F7 00

					29 01 00 00 00 00 03 F0 A5 A5		/* TEST KEY key Disable  */
					];
				qcom,mdss-dsi-on-command-state = "dsi_lp_mode";
				qcom,panel-roi-alignment=<8 1 8 1 8 1>;
			};
			hd {
				qcom,mdss-dsi-panel-width = <360>;
				qcom,mdss-dsi-panel-height = <1280>;
				qcom,mdss-dsi-h-pulse-width = <484>;
				qcom,mdss-dsi-h-back-porch = <106>;
				qcom,mdss-dsi-h-front-porch = <16>;
				qcom,mdss-dsi-h-sync-skew = <0>;
				qcom,mdss-dsi-v-pulse-width = <1282>;
				qcom,mdss-dsi-v-back-porch = <14>;
				qcom,mdss-dsi-v-front-porch = <6>;

				qcom,mdss-dsi-panel-framerate = <60>;
				qcom,mdss-dsi-panel-timings = [FE 56 3C 00 74 88 3C 56 4A 03 04 A0];
				qcom,mdss-dsi-t-clk-pre = <0x33>;
				qcom,mdss-dsi-t-clk-post = <0x0D>;
				qcom,mdss-dsi-panel-timings-phy-v2 = [
					24 1F 08 09 05 03 04 a0
					24 1F 08 09 05 03 04 a0
					24 1F 08 09 05 03 04 a0
					24 1F 08 09 05 03 04 a0
					24 1E 08 09 05 03 04 a0
				];
				qcom,mdss-dsi-on-command = [
					29 00 00 00 05 00 03 F0 5A 5A 		/* TEST KEY1 Enable */

					05 01 00 00 05 00 01 11 			/* Sleep out */

					29 00 00 00 00 00 02 C4 03			/* Dual DSI */
					29 01 00 00 00 00 02 F9 03			/* MIC disable */

					29 00 00 00 00 00 02 35 00			/* TE Vsync ON */

					29 00 00 00 00 00 02 ED 44			/* ERR_FG */

					29 00 00 00 00 00 14 C2				/* pentime control setting */
					00 00 D8 D8 00 80 2B 05
					08 0E 07 0B 05 0D 0A 15
					13 20 1E

					29 00 00 00 00 00 02 BA 00			/* scaler setup */

					29 00 00 00 00 00 05 2A 00 00 02 CF	/* CASET PASET */
					29 00 00 00 00 00 05 2B 00 00 04 FF

					29 00 00 00 00 00 24				/* Brightness condition set */
					CA
					01 00 01 00 01 00
					80 80 80
					80 80 80
					80 80 80
					80 80 80
					80 80 80
					80 80 80
					80 80 80
					80 80 80
					00 00 00
					00 00
					29 00 00 00 00 00 0B B1 54 20 1A 33 5E 8C B3 D9	00 0A	/* AID 0% */
					29 00 00 00 00 00 03 B5 BC 4A		/* ELVSS Setting:CAPS ON : acl off */
												/* defualt ELVSS is 0x0A(-4.5V),
												 * but set 0x4A(-2.9V) to avoid glitter issue (2V more diff between ELVSS and VINT)
												 */
					29 00 00 00 00 00 03 F4 AB 1E		/* VINT set */
					29 00 00 00 00 00 02 55 00			/* acl off */

					29 01 00 00 78 00 02 F7 03			/* Gamma, LTPS(AID) update wait more 100ns */
					29 00 00 00 00 00 02 F7 00

					29 01 00 00 00 00 03 F0 A5 A5		/* TEST KEY key Disable  */
				];
				qcom,mdss-dsi-on-command-state = "dsi_lp_mode";
				qcom,panel-roi-alignment=<8 1 8 1 8 1>;
			};
		};
	};
};
